VERSION "ADD"

NS_ :

BS_:

BU_: ADD

BO_ 688 ADD_ChassisFusion_0x2B0: 16 ADD
 SG_ ADDCooltFlowReqFrmADD : 79|6@0+ (0.25,0) [0|15.75] "Lpmin" Vector__XXX
 SG_ ADDFaultInfoFlag : 7|1@0+ (1,0) [0|1] "" Vector__XXX
 SG_ ADDTValFrmADD : 71|8@0+ (1,-40) [-40|215] "degC" Vector__XXX
 SG_ ADSLrnUnavlRsnFrmADD : 6|3@0+ (1,0) [0|4] "" Vector__XXX
 SG_ ADSParkSpdSwtStsFrmADD : 95|3@0+ (1,0) [0|7] "" Vector__XXX
 SG_ ADSParkSpdSwtUnavlRsnFrmADD : 3|4@0+ (1,0) [0|15] "" Vector__XXX
 SG_ APASwtStsFrmADD : 23|3@0+ (1,0) [0|7] "" Vector__XXX
 SG_ APASwtUnavlRsnFrmADD : 47|4@0+ (1,0) [0|15] "" Vector__XXX
 SG_ AutoVehCustEIPSwtFrmADD : 87|3@0+ (1,0) [0|4] "" Vector__XXX
 SG_ AutoVehCustEIPSwtRsnFrmADD : 84|2@0+ (1,0) [0|3] "" Vector__XXX
 SG_ AutoVehSrvAuthntStsFrmADD : 82|3@0+ (1,0) [0|4] "" Vector__XXX
 SG_ AutoVehSrvAuthntStsRsnFrmADD : 73|2@0+ (1,0) [0|3] "" Vector__XXX
 SG_ AvmCamTriggerModReqFrmADD : 91|2@0+ (1,0) [0|3] "" Vector__XXX
 SG_ AVPSwtStsFrmADD : 31|3@0+ (1,0) [0|7] "" Vector__XXX
 SG_ AVPSwtUnavlRsnFrmADD : 43|4@0+ (1,0) [0|15] "" Vector__XXX
 SG_ HPPBckGrLearFrmADD : 28|3@0+ (1,0) [0|7] "" Vector__XXX
 SG_ HPPBckGrLearUnavlRsnFrmADD : 55|4@0+ (1,0) [0|15] "" Vector__XXX
 SG_ HPPSwtStsFrmADD : 39|3@0+ (1,0) [0|7] "" Vector__XXX
 SG_ HPPSwtUnavlRsnFrmADD : 51|4@0+ (1,0) [0|15] "" Vector__XXX
 SG_ ParkSwtStsSigGrpChks : 15|8@0+ (1,0) [0|255] "" Vector__XXX
 SG_ ParkSwtStsSigGrpCntr : 19|4@0+ (1,0) [0|15] "" Vector__XXX
 SG_ RPASentryQuit : 92|1@0+ (1,0) [0|1] "" Vector__XXX

BO_ 693 ADD_ChassisFusion_0x2B5: 64 ADD
 SG_ ParkOutTarDirFrmADD : 143|2@0+ (1,0) [0|3] "" Vector__XXX
 SG_ ParkSlotTarFrmADD : 151|5@0+ (1,0) [0|31] "" Vector__XXX
 SG_ ParkTarPosnSigGrpChks : 135|8@0+ (1,0) [0|255] "" Vector__XXX
 SG_ ParkTarPosnSigGrpCntr : 139|4@0+ (1,0) [0|15] "" Vector__XXX
 SG_ PASBuzzerWarnMuteReqFrmADD : 119|1@0+ (1,0) [0|1] "" Vector__XXX
 SG_ PASDistanceLevSigGrpChks : 423|8@0+ (1,0) [0|255] "" Vector__XXX
 SG_ PASDistanceLevSigGrpCntr : 427|4@0+ (1,0) [0|15] "" Vector__XXX
 SG_ PASDistanceSystemGrpChks : 159|8@0+ (1,0) [0|255] "" Vector__XXX
 SG_ PASDistanceSystemGrpCntr : 163|4@0+ (1,0) [0|15] "" Vector__XXX
 SG_ PASFCBuzzerWarnFrmADD : 118|3@0+ (1,0) [0|7] "" Vector__XXX
 SG_ PASFLBuzzerSigGrpChks : 95|8@0+ (1,0) [0|255] "" Vector__XXX
 SG_ PASFLBuzzerSigGrpCntr : 99|4@0+ (1,0) [0|15] "" Vector__XXX
 SG_ PASFLBuzzerWarnFrmADD : 115|3@0+ (1,0) [0|7] "" Vector__XXX
 SG_ PASFLDistanceFrmADD : 175|10@0+ (1,0) [0|550] "cm" Vector__XXX
 SG_ PASFLDistanceLevFrmADD : 439|3@0+ (1,0) [0|7] "" Vector__XXX
 SG_ PASFMLDistanceFrmADD : 177|10@0+ (1,0) [0|550] "cm" Vector__XXX
 SG_ PASFMLDistanceLevFrmADD : 436|3@0+ (1,0) [0|7] "" Vector__XXX
 SG_ PASFMRDistanceFrmADD : 199|10@0+ (1,0) [0|550] "cm" Vector__XXX
 SG_ PASFMRDistanceLevFrmADD : 447|3@0+ (1,0) [0|7] "" Vector__XXX
 SG_ PASFRBuzzerWarnFrmADD : 111|3@0+ (1,0) [0|7] "" Vector__XXX
 SG_ PASFRDistanceFrmADD : 201|10@0+ (1,0) [0|550] "cm" Vector__XXX
 SG_ PASFRDistanceLevFrmADD : 444|3@0+ (1,0) [0|7] "" Vector__XXX
 SG_ PASFSLDistanceFrmADD : 367|10@0+ (1,0) [0|550] "cm" Vector__XXX
 SG_ PASFSLDistanceLevFrmADD : 455|3@0+ (1,0) [0|7] "" Vector__XXX
 SG_ PASFSRDistanceFrmADD : 369|10@0+ (1,0) [0|550] "cm" Vector__XXX
 SG_ PASFSRDistanceLevFrmADD : 452|3@0+ (1,0) [0|7] "" Vector__XXX
 SG_ PASRLBuzzerWarnFrmADD : 108|3@0+ (1,0) [0|7] "" Vector__XXX
 SG_ PASRLDistanceFrmADD : 223|10@0+ (1,0) [0|550] "cm" Vector__XXX
 SG_ PASRLDistanceLevFrmADD : 463|3@0+ (1,0) [0|7] "" Vector__XXX
 SG_ PASRMLDistanceFrmADD : 225|10@0+ (1,0) [0|550] "cm" Vector__XXX
 SG_ PASRMLDistanceLevFrmADD : 460|3@0+ (1,0) [0|7] "" Vector__XXX
 SG_ PASRMRDistanceFrmADD : 247|10@0+ (1,0) [0|550] "cm" Vector__XXX
 SG_ PASRMRDistanceLevFrmADD : 471|3@0+ (1,0) [0|7] "" Vector__XXX
 SG_ PASRRBuzzerWarnFrmADD : 127|3@0+ (1,0) [0|7] "" Vector__XXX
 SG_ PASRRDistanceFrmADD : 249|10@0+ (1,0) [0|550] "cm" Vector__XXX
 SG_ PASRRDistanceLevFrmADD : 468|3@0+ (1,0) [0|7] "" Vector__XXX
 SG_ PASRSLDistanceFrmADD : 391|10@0+ (1,0) [0|550] "cm" Vector__XXX
 SG_ PASRSLDistanceLevFrmADD : 479|3@0+ (1,0) [0|7] "" Vector__XXX
 SG_ PASRSRDistanceFrmADD : 393|10@0+ (1,0) [0|550] "cm" Vector__XXX
 SG_ PASRSRDistanceLevFrmADD : 476|3@0+ (1,0) [0|7] "" Vector__XXX
 SG_ PASSDWFLSideDistanceFrmADD : 271|10@0+ (1,0) [0|550] "cm" Vector__XXX
 SG_ PASSDWFLSideDistanceLevFrmADD : 487|3@0+ (1,0) [0|7] "" Vector__XXX
 SG_ PASSDWFMLSideDistanceFrmADD : 273|10@0+ (1,0) [0|550] "cm" Vector__XXX
 SG_ PASSDWFMLSideDistanceLevFrmADD : 484|3@0+ (1,0) [0|7] "" Vector__XXX
 SG_ PASSDWFMRSideDistanceFrmADD : 295|10@0+ (1,0) [0|550] "cm" Vector__XXX
 SG_ PASSDWFMRSideDistanceLevFrmADD : 495|3@0+ (1,0) [0|7] "" Vector__XXX
 SG_ PASSDWFRSideDistanceFrmADD : 297|10@0+ (1,0) [0|550] "cm" Vector__XXX
 SG_ PASSDWFRSideDistanceLevFrmADD : 492|3@0+ (1,0) [0|7] "" Vector__XXX
 SG_ PASSDWRLSideDistanceFrmADD : 319|10@0+ (1,0) [0|550] "cm" Vector__XXX
 SG_ PASSDWRLSideDistanceLevFrmADD : 503|3@0+ (1,0) [0|7] "" Vector__XXX
 SG_ PASSDWRMLSideDistanceFrmADD : 321|10@0+ (1,0) [0|550] "cm" Vector__XXX
 SG_ PASSDWRMLSideDistanceLevFrmADD : 500|3@0+ (1,0) [0|7] "" Vector__XXX
 SG_ PASSDWRMRSideDistanceFrmADD : 343|10@0+ (1,0) [0|550] "cm" Vector__XXX
 SG_ PASSDWRMRSideDistanceLevFrmADD : 511|3@0+ (1,0) [0|7] "" Vector__XXX
 SG_ PASSDWRRSideDistanceFrmADD : 345|10@0+ (1,0) [0|550] "cm" Vector__XXX
 SG_ PASSDWRRSideDistanceLevFrmADD : 508|3@0+ (1,0) [0|7] "" Vector__XXX

BO_ 775 ADD_ChassisFusion_0x307: 32 ADD
 SG_ ParkProgressSigLFPosXFrmADD : 55|16@0+ (0.01,-327.67) [-327.67|327.68] "m" Vector__XXX
 SG_ ParkProgressSigLFPosYFrmADD : 71|16@0+ (0.01,-327.67) [-327.67|327.68] "m" Vector__XXX
 SG_ ParkProgressSigLRPosXFrmADD : 87|16@0+ (0.01,-327.67) [-327.67|327.68] "m" Vector__XXX
 SG_ ParkProgressSigLRPosYFrmADD : 103|16@0+ (0.01,-327.67) [-327.67|327.68] "m" Vector__XXX
 SG_ ParkProgressSigRFPosXFrmADD : 119|16@0+ (0.01,-327.67) [-327.67|327.68] "m" Vector__XXX
 SG_ ParkProgressSigRFPosYFrmADD : 135|16@0+ (0.01,-327.67) [-327.67|327.68] "m" Vector__XXX
 SG_ ParkProgressSigRRPosXFrmADD : 151|16@0+ (0.01,-327.67) [-327.67|327.68] "m" Vector__XXX
 SG_ ParkProgressSigRRPosYFrmADD : 167|16@0+ (0.01,-327.67) [-327.67|327.68] "m" Vector__XXX
 SG_ PASProgressSigGrpChks : 39|8@0+ (1,0) [0|255] "" Vector__XXX
 SG_ PASProgressSigGrpCntr : 43|4@0+ (1,0) [0|15] "" Vector__XXX
 SG_ PASSubFunAvaiFrmADD : 15|3@0+ (1,0) [0|7] "" Vector__XXX
 SG_ PASWorkingModeFrmADD : 23|3@0+ (1,0) [0|7] "" Vector__XXX
 SG_ PASWorkingModeSigGrpChks : 7|8@0+ (1,0) [0|255] "" Vector__XXX
 SG_ PASWorkingModeSigGrpCntr : 11|4@0+ (1,0) [0|15] "" Vector__XXX

BO_ 873 ADD_ChassisFusion_0x369: 8 ADD
 SG_ LowPwrReqFrLdrFrmADD : 23|2@0+ (1,0) [0|2] "" Vector__XXX
 SG_ LowPwrReqFrRdrFrmADD : 21|2@0+ (1,0) [0|2] "" Vector__XXX

BO_ 238 ADD_ChassisFusion_0xEE: 32 ADD
 SG_ ADD2BLEMForRPA00 : 7|64@0+ (1,0) [0|1.84467440737096E+019] "" Vector__XXX
 SG_ ADD2BLEMForRPA00FV : 215|16@0+ (1,0) [0|65535] "" Vector__XXX
 SG_ ADD2BLEMForRPA00MAC : 231|32@0+ (1,0) [0|0] "" Vector__XXX
 SG_ ADD2BLEMForRPA01 : 71|64@0+ (1,0) [0|1.84467440737096E+019] "" Vector__XXX
 SG_ ADD2BLEMForRPA02 : 135|64@0+ (1,0) [0|1.84467440737096E+019] "" Vector__XXX
 SG_ ADD2BLEMForRPA03 : 199|16@0+ (1,0) [0|65535] "" Vector__XXX

BO_ 239 ADD_ChassisFusion_0xEF: 24 ADD
 SG_ ADDIMUSigGrpChks : 7|8@0+ (1,0) [0|255] "" Vector__XXX
 SG_ ADDIMUSigGrpCntr : 11|4@0+ (1,0) [0|15] "" Vector__XXX
 SG_ XAccelStaFrmADD : 33|2@0+ (1,0) [0|3] "" Vector__XXX
 SG_ XAccelValFrmADD : 23|20@0+ (0.001,-98.1) [-98.1|98.1] "m/s^2" Vector__XXX
 SG_ XAngRateStaFrmADD : 177|2@0+ (1,0) [0|3] "" Vector__XXX
 SG_ XAngRateValFrmADD : 47|22@0+ (1E-005,-8.72665) [-8.72665|8.72665] "rad/s" Vector__XXX
 SG_ YAccelStaFrmADD : 161|2@0+ (1,0) [0|3] "" Vector__XXX
 SG_ YAccelValFrmADD : 71|20@0+ (0.001,-98.1) [-98.1|98.1] "m/s^2" Vector__XXX
 SG_ YAngRateStaFrmADD : 163|2@0+ (1,0) [0|3] "" Vector__XXX
 SG_ YAngRateValFrmADD : 95|22@0+ (1E-005,-8.72665) [-8.72665|8.72665] "rad/s" Vector__XXX
 SG_ ZAccelStaFrmADD : 171|2@0+ (1,0) [0|3] "" Vector__XXX
 SG_ ZAccelValFrmADD : 119|20@0+ (0.001,-98.1) [-98.1|98.1] "m/s^2" Vector__XXX
 SG_ ZAngRateStaFrmADD : 169|2@0+ (1,0) [0|3] "" Vector__XXX
 SG_ ZAngRateValFrmADD : 143|22@0+ (1E-005,-8.72665) [-8.72665|8.72665] "rad/s" Vector__XXX

BO_ 1331 ADDChassisFusionCanfdNMFrA: 8 ADD
 SG_ ADDChassisBkpActiveWakeup : 12|1@0+ (1,0) [0|1] "" Vector__XXX
 SG_ ADDChassisBkpNodeAddress : 7|8@0+ (1,0) [0|255] "" Vector__XXX
 SG_ ADDChassisBkpRepeatMsgReq : 8|1@0+ (1,0) [0|1] "" Vector__XXX
 SG_ ADDChassisBkpRepeatMsgSt : 16|1@0+ (1,0) [0|1] "" Vector__XXX
 SG_ NMKeepAwkRsnADD : 48|9@0+ (1,0) [0|511] "" Vector__XXX
 SG_ UDB17ADD : 17|1@0+ (1,0) [0|1] "" Vector__XXX
 SG_ UDB18ADD : 18|1@0+ (1,0) [0|1] "" Vector__XXX
 SG_ UDB19ADD : 19|1@0+ (1,0) [0|1] "" Vector__XXX
 SG_ UDB20ADD : 20|1@0+ (1,0) [0|1] "" Vector__XXX
 SG_ UDB21ADD : 21|1@0+ (1,0) [0|1] "" Vector__XXX
 SG_ UDB22ADD : 22|1@0+ (1,0) [0|1] "" Vector__XXX
 SG_ UDB23ADD : 23|1@0+ (1,0) [0|1] "" Vector__XXX
 SG_ UDB24ADD : 24|1@0+ (1,0) [0|1] "" Vector__XXX
 SG_ UDB25ADD : 25|1@0+ (1,0) [0|1] "" Vector__XXX
 SG_ UDB26ADD : 26|1@0+ (1,0) [0|1] "" Vector__XXX
 SG_ UDB27ADD : 27|1@0+ (1,0) [0|1] "" Vector__XXX
 SG_ UDB28ADD : 28|1@0+ (1,0) [0|1] "" Vector__XXX
 SG_ UDB29ADD : 29|1@0+ (1,0) [0|1] "" Vector__XXX
 SG_ UDB30ADD : 30|1@0+ (1,0) [0|1] "" Vector__XXX
 SG_ UDB31ADD : 31|1@0+ (1,0) [0|1] "" Vector__XXX
 SG_ UDB32ADD : 32|1@0+ (1,0) [0|1] "" Vector__XXX
 SG_ UDB33ADD : 33|1@0+ (1,0) [0|1] "" Vector__XXX
 SG_ UDB34ADD : 34|1@0+ (1,0) [0|1] "" Vector__XXX
 SG_ UDB35ADD : 35|1@0+ (1,0) [0|1] "" Vector__XXX
 SG_ UDB36ADD : 36|1@0+ (1,0) [0|1] "" Vector__XXX
 SG_ UDB37ADD : 37|1@0+ (1,0) [0|1] "" Vector__XXX
 SG_ UDB38ADD : 38|1@0+ (1,0) [0|1] "" Vector__XXX
 SG_ UDB39ADD : 39|1@0+ (1,0) [0|1] "" Vector__XXX
 SG_ UDB40ADD : 40|1@0+ (1,0) [0|1] "" Vector__XXX
 SG_ UDB41ADD : 41|1@0+ (1,0) [0|1] "" Vector__XXX
 SG_ UDB42ADD : 42|1@0+ (1,0) [0|1] "" Vector__XXX
 SG_ UDB43ADD : 43|1@0+ (1,0) [0|1] "" Vector__XXX
 SG_ UDB44ADD : 44|1@0+ (1,0) [0|1] "" Vector__XXX
 SG_ UDB45ADD : 45|1@0+ (1,0) [0|1] "" Vector__XXX
 SG_ UDB46ADD : 46|1@0+ (1,0) [0|1] "" Vector__XXX
 SG_ UDB47ADD : 47|1@0+ (1,0) [0|1] "" Vector__XXX

BO_ 1326 ADDChassisFusionCanfdNMFrB: 8 ADD
 SG_ ADDChassisBkpActiveWakeup1 : 12|1@0+ (1,0) [0|1] "" Vector__XXX
 SG_ ADDChassisBkpNodeAddress1 : 7|8@0+ (1,0) [0|255] "" Vector__XXX
 SG_ ADDChassisBkpRepeatMsgReq1 : 8|1@0+ (1,0) [0|1] "" Vector__XXX
 SG_ ADDChassisBkpRepeatMsgSt1 : 16|1@0+ (1,0) [0|1] "" Vector__XXX
 SG_ NMKeepAwkRsnADD : 48|9@0+ (1,0) [0|511] "" Vector__XXX
 SG_ UDB17ADD : 17|1@0+ (1,0) [0|1] "" Vector__XXX
 SG_ UDB18ADD : 18|1@0+ (1,0) [0|1] "" Vector__XXX
 SG_ UDB19ADD : 19|1@0+ (1,0) [0|1] "" Vector__XXX
 SG_ UDB20ADD : 20|1@0+ (1,0) [0|1] "" Vector__XXX
 SG_ UDB21ADD : 21|1@0+ (1,0) [0|1] "" Vector__XXX
 SG_ UDB22ADD : 22|1@0+ (1,0) [0|1] "" Vector__XXX
 SG_ UDB23ADD : 23|1@0+ (1,0) [0|1] "" Vector__XXX
 SG_ UDB24ADD : 24|1@0+ (1,0) [0|1] "" Vector__XXX
 SG_ UDB25ADD : 25|1@0+ (1,0) [0|1] "" Vector__XXX
 SG_ UDB26ADD : 26|1@0+ (1,0) [0|1] "" Vector__XXX
 SG_ UDB27ADD : 27|1@0+ (1,0) [0|1] "" Vector__XXX
 SG_ UDB28ADD : 28|1@0+ (1,0) [0|1] "" Vector__XXX
 SG_ UDB29ADD : 29|1@0+ (1,0) [0|1] "" Vector__XXX
 SG_ UDB30ADD : 30|1@0+ (1,0) [0|1] "" Vector__XXX
 SG_ UDB31ADD : 31|1@0+ (1,0) [0|1] "" Vector__XXX
 SG_ UDB32ADD : 32|1@0+ (1,0) [0|1] "" Vector__XXX
 SG_ UDB33ADD : 33|1@0+ (1,0) [0|1] "" Vector__XXX
 SG_ UDB34ADD : 34|1@0+ (1,0) [0|1] "" Vector__XXX
 SG_ UDB35ADD : 35|1@0+ (1,0) [0|1] "" Vector__XXX
 SG_ UDB36ADD : 36|1@0+ (1,0) [0|1] "" Vector__XXX
 SG_ UDB37ADD : 37|1@0+ (1,0) [0|1] "" Vector__XXX
 SG_ UDB38ADD : 38|1@0+ (1,0) [0|1] "" Vector__XXX
 SG_ UDB39ADD : 39|1@0+ (1,0) [0|1] "" Vector__XXX
 SG_ UDB40ADD : 40|1@0+ (1,0) [0|1] "" Vector__XXX
 SG_ UDB41ADD : 41|1@0+ (1,0) [0|1] "" Vector__XXX
 SG_ UDB42ADD : 42|1@0+ (1,0) [0|1] "" Vector__XXX
 SG_ UDB43ADD : 43|1@0+ (1,0) [0|1] "" Vector__XXX
 SG_ UDB44ADD : 44|1@0+ (1,0) [0|1] "" Vector__XXX
 SG_ UDB45ADD : 45|1@0+ (1,0) [0|1] "" Vector__XXX
 SG_ UDB46ADD : 46|1@0+ (1,0) [0|1] "" Vector__XXX
 SG_ UDB47ADD : 47|1@0+ (1,0) [0|1] "" Vector__XXX

BO_ 487 BCP_ChassisFusion_0x1E7: 24 Vector__XXX
 SG_ BcpBrkSysIndcnBkpSigGrpChks : 103|8@0+ (1,0) [0|255] ""  ADD
 SG_ BcpBrkSysIndcnBkpSigGrpCntr : 107|4@0+ (1,0) [0|15] ""  ADD
 SG_ BrkSysBrkPedlAppld : 111|1@0+ (1,0) [0|1] ""  ADD
 SG_ BrkSysBrkPedlAppldVld : 110|2@0+ (1,0) [0|3] ""  ADD
 SG_ BrkSysEnaActvCtrlByDrvr : 108|1@0+ (1,0) [0|1] ""  ADD
 SG_ BrkSysFTarDrvr : 127|11@0+ (64,-131008) [-131008|0] "N"  ADD
 SG_ BrkSysFTarDrvrVld : 132|2@0+ (1,0) [0|3] ""  ADD
 SG_ BrkSysPRednPotnl : 119|8@0+ (0.5,0) [0|120] "bar"  ADD
 SG_ BrkSysPRednPotnlVld : 130|2@0+ (1,0) [0|3] ""  ADD
 SG_ BrkSysWarnLampReq : 143|2@0+ (1,0) [0|3] ""  ADD

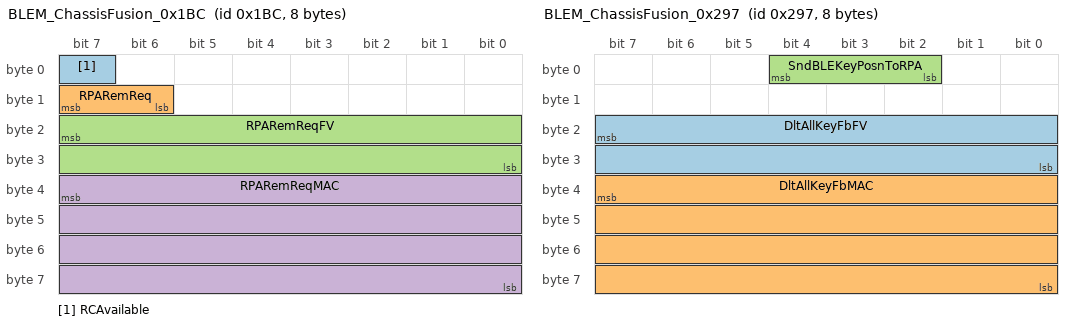
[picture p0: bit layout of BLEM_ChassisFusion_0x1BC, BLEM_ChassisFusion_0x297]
BO_ 444 BLEM_ChassisFusion_0x1BC: 8 Vector__XXX
 SG_ RCAvailable : 7|1@0+ (1,0) [0|1] ""  ADD
 SG_ RPARemReq : 15|2@0+ (1,0) [0|3] ""  ADD
 SG_ RPARemReqFV : 23|16@0+ (1,0) [0|65535] ""  ADD
 SG_ RPARemReqMAC : 39|32@0+ (1,0) [0|0] ""  ADD

BO_ 657 BLEM_ChassisFusion_0x291: 64 Vector__XXX
 SG_ BLEM2VCCDForLocn10 : 7|32@0+ (1,0) [0|4294967295] ""  ADD
 SG_ BLEM2VCCDForLocn11 : 39|32@0+ (1,0) [0|4294967295] ""  ADD
 SG_ BLEM2VCCDForLocn12 : 71|32@0+ (1,0) [0|4294967295] ""  ADD
 SG_ BLEM2VCCDForLocn13 : 103|32@0+ (1,0) [0|4294967295] ""  ADD
 SG_ BLEM2VCCDForLocn14 : 135|32@0+ (1,0) [0|4294967295] ""  ADD
 SG_ BLEM2VCCDForLocn15 : 167|32@0+ (1,0) [0|4294967295] ""  ADD
 SG_ BLEM2VCCDForLocn16 : 199|32@0+ (1,0) [0|4294967295] ""  ADD
 SG_ BLEM2VCCDForLocn17 : 231|32@0+ (1,0) [0|4294967295] ""  ADD
 SG_ BLEM2VCCDForLocn18 : 263|32@0+ (1,0) [0|4294967295] ""  ADD
 SG_ BLEM2VCCDForLocn19 : 295|32@0+ (1,0) [0|4294967295] ""  ADD
 SG_ BLEM2VCCDForLocn1A : 327|32@0+ (1,0) [0|4294967295] ""  ADD
 SG_ BLEM2VCCDForLocn1B : 359|32@0+ (1,0) [0|4294967295] ""  ADD
 SG_ BLEM2VCCDForLocn1C : 391|32@0+ (1,0) [0|4294967295] ""  ADD
 SG_ BLEM2VCCDForLocn1D : 423|32@0+ (1,0) [0|4294967295] ""  ADD
 SG_ BLEM2VCCDForLocn1F : 455|16@0+ (1,0) [0|65535] ""  ADD
 SG_ BLEM2VCCDForLocn1FV : 471|16@0+ (1,0) [0|65535] ""  ADD
 SG_ BLEM2VCCDForLocn1MAC : 487|32@0+ (1,0) [0|0] ""  ADD

BO_ 663 BLEM_ChassisFusion_0x297: 8 Vector__XXX
 SG_ DltAllKeyFbFV : 23|16@0+ (1,0) [0|65535] ""  ADD
 SG_ DltAllKeyFbMAC : 39|32@0+ (1,0) [0|0] ""  ADD
 SG_ SndBLEKeyPosnToRPA : 4|3@0+ (1,0) [0|7] ""  ADD

BO_ 665 BLEM_ChassisFusion_0x299: 64 Vector__XXX
 SG_ BLEM2VCCDForLocn20 : 7|32@0+ (1,0) [0|4294967295] ""  ADD
 SG_ BLEM2VCCDForLocn21 : 39|32@0+ (1,0) [0|4294967295] ""  ADD
 SG_ BLEM2VCCDForLocn22 : 71|32@0+ (1,0) [0|4294967295] ""  ADD
 SG_ BLEM2VCCDForLocn23 : 103|32@0+ (1,0) [0|4294967295] ""  ADD
 SG_ BLEM2VCCDForLocn24 : 135|32@0+ (1,0) [0|4294967295] ""  ADD
 SG_ BLEM2VCCDForLocn25 : 167|32@0+ (1,0) [0|4294967295] ""  ADD
 SG_ BLEM2VCCDForLocn26 : 199|32@0+ (1,0) [0|4294967295] ""  ADD
 SG_ BLEM2VCCDForLocn27 : 231|32@0+ (1,0) [0|4294967295] ""  ADD
 SG_ BLEM2VCCDForLocn28 : 263|32@0+ (1,0) [0|4294967295] ""  ADD
 SG_ BLEM2VCCDForLocn29 : 295|32@0+ (1,0) [0|4294967295] ""  ADD
 SG_ BLEM2VCCDForLocn2A : 327|32@0+ (1,0) [0|4294967295] ""  ADD
 SG_ BLEM2VCCDForLocn2B : 359|32@0+ (1,0) [0|4294967295] ""  ADD
 SG_ BLEM2VCCDForLocn2C : 391|32@0+ (1,0) [0|4294967295] ""  ADD
 SG_ BLEM2VCCDForLocn2D : 423|32@0+ (1,0) [0|4294967295] ""  ADD
 SG_ BLEM2VCCDForLocn2F : 455|16@0+ (1,0) [0|65535] ""  ADD
 SG_ BLEM2VCCDForLocn2FV : 471|16@0+ (1,0) [0|65535] ""  ADD
 SG_ BLEM2VCCDForLocn2MAC : 487|32@0+ (1,0) [0|0] ""  ADD

BO_ 758 BLEM_ChassisFusion_0x2F6: 16 Vector__XXX
 SG_ FrntLeTyrePVal : 31|8@0+ (2.75,0) [0|698.5] "kpa"  ADD
 SG_ FrntLeTyrePWarn : 19|2@0+ (1,0) [0|3] ""  ADD
 SG_ FrntRiTyrePVal : 39|8@0+ (2.75,0) [0|698.5] "kpa"  ADD
 SG_ FrntRiTyrePWarn : 17|2@0+ (1,0) [0|3] ""  ADD
 SG_ ReLeTyrePVal : 7|8@0+ (2.75,0) [0|698.5] "kpa"  ADD
 SG_ ReLeTyrePWarn : 23|2@0+ (1,0) [0|3] ""  ADD
 SG_ ReRiTyrePVal : 15|8@0+ (2.75,0) [0|698.5] "kpa"  ADD
 SG_ ReRiTyrePWarn : 21|2@0+ (1,0) [0|3] ""  ADD
 SG_ TyrePWarnFV : 87|16@0+ (1,0) [0|65535] ""  ADD
 SG_ TyrePWarnMAC : 103|32@0+ (1,0) [0|4294967295] ""  ADD

BO_ 817 BLEM_ChassisFusion_0x331: 64 Vector__XXX
 SG_ BLEM2VCCDForLocn40 : 135|32@0+ (1,0) [0|4294967295] ""  ADD
 SG_ BLEM2VCCDForLocn41 : 167|32@0+ (1,0) [0|4294967295] ""  ADD
 SG_ BLEM2VCCDForLocn42 : 199|32@0+ (1,0) [0|4294967295] ""  ADD
 SG_ BLEM2VCCDForLocn43 : 231|32@0+ (1,0) [0|4294967295] ""  ADD
 SG_ BLEM2VCCDForLocn44 : 7|32@0+ (1,0) [0|4294967295] ""  ADD
 SG_ BLEM2VCCDForLocn45 : 39|32@0+ (1,0) [0|4294967295] ""  ADD
 SG_ BLEM2VCCDForLocn46 : 71|32@0+ (1,0) [0|4294967295] ""  ADD
 SG_ BLEM2VCCDForLocn47 : 103|32@0+ (1,0) [0|4294967295] ""  ADD
 SG_ BLEM2VCCDForLocn48 : 263|32@0+ (1,0) [0|4294967295] ""  ADD
 SG_ BLEM2VCCDForLocn49 : 295|32@0+ (1,0) [0|4294967295] ""  ADD
 SG_ BLEM2VCCDForLocn4A : 327|32@0+ (1,0) [0|4294967295] ""  ADD
 SG_ BLEM2VCCDForLocn4B : 359|32@0+ (1,0) [0|4294967295] ""  ADD
 SG_ BLEM2VCCDForLocn4C : 391|32@0+ (1,0) [0|4294967295] ""  ADD
 SG_ BLEM2VCCDForLocn4D : 423|32@0+ (1,0) [0|4294967295] ""  ADD
 SG_ BLEM2VCCDForLocn4F : 455|16@0+ (1,0) [0|65535] ""  ADD
 SG_ BLEM2VCCDForLocn4FV : 471|16@0+ (1,0) [0|65535] ""  ADD
 SG_ BLEM2VCCDForLocn4MAC : 487|32@0+ (1,0) [0|0] ""  ADD

BO_ 825 BLEM_ChassisFusion_0x339: 32 Vector__XXX
 SG_ BLEM2ADDForRPA00 : 7|64@0+ (1,0) [0|1.84467440737096E+019] ""  ADD
 SG_ BLEM2ADDForRPA00FV : 215|16@0+ (1,0) [0|65535] ""  ADD
 SG_ BLEM2ADDForRPA00MAC : 231|32@0+ (1,0) [0|0] ""  ADD
 SG_ BLEM2ADDForRPA01 : 71|64@0+ (1,0) [0|1.84467440737096E+019] ""  ADD
 SG_ BLEM2ADDForRPA02 : 135|64@0+ (1,0) [0|1.84467440737096E+019] ""  ADD
 SG_ BLEM2ADDForRPA03 : 199|16@0+ (1,0) [0|65535] ""  ADD

BO_ 826 BLEM_ChassisFusion_0x33A: 64 Vector__XXX
 SG_ BLEM2VCCDForLocn30 : 7|32@0+ (1,0) [0|4294967295] ""  ADD
 SG_ BLEM2VCCDForLocn31 : 39|32@0+ (1,0) [0|4294967295] ""  ADD
 SG_ BLEM2VCCDForLocn32 : 71|32@0+ (1,0) [0|4294967295] ""  ADD
 SG_ BLEM2VCCDForLocn33 : 103|32@0+ (1,0) [0|4294967295] ""  ADD
 SG_ BLEM2VCCDForLocn34 : 135|32@0+ (1,0) [0|4294967295] ""  ADD
 SG_ BLEM2VCCDForLocn35 : 167|32@0+ (1,0) [0|4294967295] ""  ADD
 SG_ BLEM2VCCDForLocn36 : 199|32@0+ (1,0) [0|4294967295] ""  ADD
 SG_ BLEM2VCCDForLocn37 : 231|32@0+ (1,0) [0|4294967295] ""  ADD
 SG_ BLEM2VCCDForLocn38 : 263|32@0+ (1,0) [0|4294967295] ""  ADD
 SG_ BLEM2VCCDForLocn39 : 295|32@0+ (1,0) [0|4294967295] ""  ADD
 SG_ BLEM2VCCDForLocn3A : 327|32@0+ (1,0) [0|4294967295] ""  ADD
 SG_ BLEM2VCCDForLocn3B : 359|32@0+ (1,0) [0|4294967295] ""  ADD
 SG_ BLEM2VCCDForLocn3C : 391|32@0+ (1,0) [0|4294967295] ""  ADD
 SG_ BLEM2VCCDForLocn3D : 423|32@0+ (1,0) [0|4294967295] ""  ADD
 SG_ BLEM2VCCDForLocn3F : 455|16@0+ (1,0) [0|65535] ""  ADD
 SG_ BLEM2VCCDForLocn3FV : 471|16@0+ (1,0) [0|65535] ""  ADD
 SG_ BLEM2VCCDForLocn3MAC : 487|32@0+ (1,0) [0|0] ""  ADD

BO_ 827 BLEM_ChassisFusion_0x33B: 64 Vector__XXX
 SG_ BLEM2VCCDForRkeReq00 : 7|32@0+ (1,0) [0|4294967295] ""  ADD
 SG_ BLEM2VCCDForRkeReq01 : 39|32@0+ (1,0) [0|4294967295] ""  ADD
 SG_ BLEM2VCCDForRkeReq02 : 71|32@0+ (1,0) [0|4294967295] ""  ADD
 SG_ BLEM2VCCDForRkeReq03 : 103|32@0+ (1,0) [0|4294967295] ""  ADD
 SG_ BLEM2VCCDForRkeReq04 : 135|32@0+ (1,0) [0|4294967295] ""  ADD
 SG_ BLEM2VCCDForRkeReq05 : 167|32@0+ (1,0) [0|4294967295] ""  ADD
 SG_ BLEM2VCCDForRkeReq06 : 199|32@0+ (1,0) [0|4294967295] ""  ADD
 SG_ BLEM2VCCDForRkeReq07 : 231|32@0+ (1,0) [0|4294967295] ""  ADD
 SG_ BLEM2VCCDForRkeReq08 : 263|32@0+ (1,0) [0|4294967295] ""  ADD
 SG_ BLEM2VCCDForRkeReq09 : 295|32@0+ (1,0) [0|4294967295] ""  ADD
 SG_ BLEM2VCCDForRkeReq10 : 327|32@0+ (1,0) [0|4294967295] ""  ADD
 SG_ BLEM2VCCDForRkeReq11 : 359|32@0+ (1,0) [0|4294967295] ""  ADD
 SG_ BLEM2VCCDForRkeReq12 : 391|32@0+ (1,0) [0|4294967295] ""  ADD
 SG_ BLEM2VCCDForRkeReq13 : 423|32@0+ (1,0) [0|4294967295] ""  ADD
 SG_ BLEM2VCCDForRkeReq14 : 455|16@0+ (1,0) [0|65535] ""  ADD
 SG_ BLEM2VCCDForRkeReqFV : 471|16@0+ (1,0) [0|65535] ""  ADD
 SG_ BLEM2VCCDForRkeReqMAC : 487|32@0+ (1,0) [0|0] ""  ADD

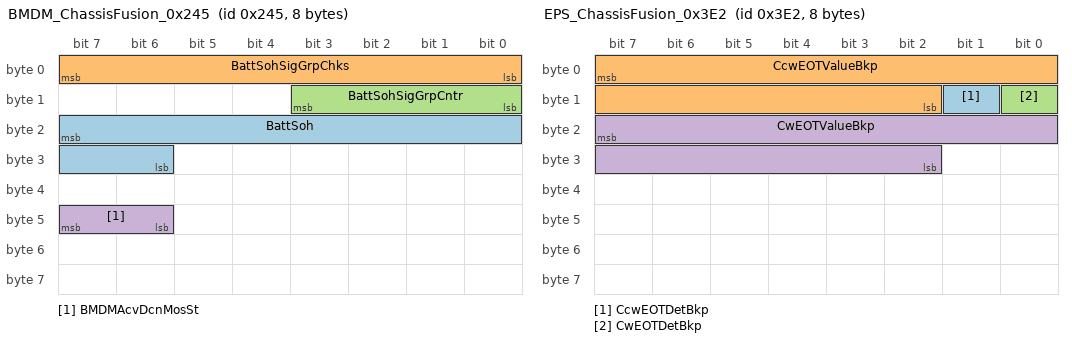
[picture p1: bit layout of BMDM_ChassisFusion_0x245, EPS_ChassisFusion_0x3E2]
BO_ 581 BMDM_ChassisFusion_0x245: 8 Vector__XXX
 SG_ BattSoh : 23|10@0+ (0.1,0) [0|102.3] "%"  ADD
 SG_ BattSohSigGrpChks : 7|8@0+ (1,0) [0|255] ""  ADD
 SG_ BattSohSigGrpCntr : 11|4@0+ (1,0) [0|15] ""  ADD
 SG_ BMDMAcvDcnMosSt : 47|2@0+ (1,0) [0|3] ""  ADD

BO_ 355 EPS_ChassisFusion_0x163: 16 Vector__XXX
 SG_ AVPHPPCtrlAvlStsBkp : 71|2@0+ (1,0) [0|3] ""  ADD
 SG_ AVPHPPCtrStsBkp : 56|1@0+ (1,0) [0|1] ""  ADD
 SG_ AVPHPPReqFbStsBkp : 59|3@0+ (1,0) [0|7] ""  ADD
 SG_ AVPHPPReqFltStsBkp : 63|4@0+ (1,0) [0|15] ""  ADD
 SG_ EPSAVPHPPCtrlStsBkpSigGrpChks : 47|8@0+ (1,0) [0|255] ""  ADD
 SG_ EPSAVPHPPCtrlStsBkpSigGrpCntr : 51|4@0+ (1,0) [0|15] ""  ADD
 SG_ FailrStsBkp : 38|3@0+ (1,0) [0|7] ""  ADD
 SG_ FailrStsBkpSigGrpChks : 31|8@0+ (1,0) [0|255] ""  ADD
 SG_ FailrStsBkpSigGrpCntr : 35|4@0+ (1,0) [0|15] ""  ADD

BO_ 994 EPS_ChassisFusion_0x3E2: 8 Vector__XXX
 SG_ CcwEOTDetBkp : 9|1@0+ (1,0) [0|1] ""  ADD
 SG_ CcwEOTValueBkp : 7|14@0+ (0.0625,0) [0|780] ""  ADD
 SG_ CwEOTDetBkp : 8|1@0+ (1,0) [0|1] ""  ADD
 SG_ CwEOTValueBkp : 23|14@0+ (0.0625,-780) [-780|0] "deg"  ADD

BO_ 200 EPS_ChassisFusion_0xC8: 16 Vector__XXX
 SG_ PinionAglSpdBkpV2C : 71|12@0- (1,0) [-2048|2047] "deg/s"  ADD
 SG_ PinionSteerAglBkp : 22|15@0- (0.0625,0) [-780|780] "°(deg)"  ADD
 SG_ PinionSteerAglBkpV2C : 87|15@0- (0.0625,0) [-780|780] "°（deg）"  ADD
 SG_ PinionSteerAglSpdBkp : 55|12@0- (1,0) [-2048|2047] "deg/s"  ADD
 SG_ PinionSteerAglSpdVldBkp : 59|1@0+ (1,0) [0|1] ""  ADD
 SG_ PinionSteerAglSpdVldBkpV2C : 75|1@0+ (1,0) [0|1] ""  ADD
 SG_ PinionSteerAglVldBkp : 23|1@0+ (1,0) [0|1] ""  ADD
 SG_ PinionSteerAglVldBkpV2C : 74|1@0+ (1,0) [0|1] ""  ADD
 SG_ SteeringWhlSignalBkpSigGrpChks : 7|8@0+ (1,0) [0|255] ""  ADD
 SG_ SteeringWhlSignalBkpSigGrpCntr : 11|4@0+ (1,0) [0|15] ""  ADD
 SG_ SteerWhlTqBkp : 39|11@0- (0.01,0) [-10.24|10.23] "Nm"  ADD
 SG_ SteerWhlTqVldBkp : 44|1@0+ (1,0) [0|1] ""  ADD

BO_ 515 FZCU_ChassisFusion_0x203: 16 Vector__XXX
 SG_ VCUExtmPfmncMod : 28|1@0+ (1,0) [0|1] ""  ADD
 SG_ VCUTrlrModStSts : 39|1@0+ (1,0) [0|1] ""  ADD
 SG_ VCUWashModStSts : 27|1@0+ (1,0) [0|1] ""  ADD
 SG_ VDMMueEstdForADD : 38|4@0+ (0.1,0) [0|1.5] ""  ADD

BO_ 656 FZCU_ChassisFusion_0x290: 32 Vector__XXX
 SG_ ADDCooltCircFlowEstimd : 119|10@0+ (0.05,0) [0|51.15] "L/min"  ADD
 SG_ AmbTEstimd : 103|16@0+ (0.01,-80) [-80|175] "degC"  ADD
 SG_ AmbTEstimdVld : 91|1@0+ (1,0) [0|1] ""  ADD
 SG_ EdsCircCooltT : 151|16@0+ (0.01,-80) [-80|175] "degC"  ADD
 SG_ EdsCircCooltTSnsrU : 167|16@0+ (0.1,0) [0|5000] "mV"  ADD
 SG_ EdsCircCooltTVld : 89|1@0+ (1,0) [0|1] ""  ADD
 SG_ InsEgyCnsSigGrpChks : 7|8@0+ (1,0) [0|255] ""  ADD
 SG_ InsEgyCnsSigGrpCntr : 11|4@0+ (1,0) [0|15] ""  ADD
 SG_ LRR2LoPwrSplySts : 125|1@0+ (1,0) [0|1] ""  ADD
 SG_ LRRLoPwrSplySts : 88|1@0+ (1,0) [0|1] ""  ADD
 SG_ VCUBattOverHeatWarn : 201|1@0+ (1,0) [0|1] ""  ADD
 SG_ VCUDrvMotFltWarn : 200|1@0+ (1,0) [0|1] ""  ADD
 SG_ VCUDrvMotOverHeatWarn : 215|1@0+ (1,0) [0|1] ""  ADD
 SG_ VCUDrvSysLimdWarn : 214|1@0+ (1,0) [0|1] ""  ADD
 SG_ VCUEgyCnsInCurDrvCyc : 23|18@0+ (0.01,-200) [-200|200] "kwh"  ADD
 SG_ VCUEstimdCrsRng : 71|11@0+ (1,0) [0|2046] ""  ADD
 SG_ VCUEstimdCrsRngForCltc : 74|11@0+ (1,0) [0|2047] ""  ADD
 SG_ VCUEstimdCrsRngVld : 76|1@0+ (1,0) [0|1] ""  ADD
 SG_ VCUGearChgFailInde : 207|4@0+ (1,0) [0|15] ""  ADD
 SG_ VCUHvBattSysFltIndcr : 213|1@0+ (1,0) [0|1] ""  ADD
 SG_ VCUHvBattSysFltWarn : 212|1@0+ (1,0) [0|1] ""  ADD
 SG_ VCUHvPwrSysCutOff : 211|1@0+ (1,0) [0|1] ""  ADD
 SG_ VCUHVSysFltWarnSts : 199|4@0+ (1,0) [0|15] ""  ADD
 SG_ VCUInsEgyCnsDurgDrvg : 55|11@0+ (0.1,-100) [-100|100] ""  ADD
 SG_ VCUInsEgyCnsDurgStsl : 32|9@0+ (0.1,0) [0|50] ""  ADD
 SG_ VCUInsEgyCnsFlg : 60|1@0+ (1,0) [0|1] ""  ADD
 SG_ VCULoSocWarngMsg : 203|2@0+ (1,0) [0|2] ""  ADD
 SG_ VCUPrpsnPwrDrt : 210|1@0+ (1,0) [0|1] ""  ADD
 SG_ VCUThermRunawayErrAlrm : 209|1@0+ (1,0) [0|1] ""  ADD
 SG_ VCUVehSysFltWarn : 208|1@0+ (1,0) [0|1] ""  ADD
 SG_ VehSysFltWarnSigGrpChks : 191|8@0+ (1,0) [0|255] ""  ADD
 SG_ VehSysFltWarnSigGrpCntr : 195|4@0+ (1,0) [0|15] ""  ADD

BO_ 188 FZCU_ChassisFusion_0xBC: 64 Vector__XXX
 SG_ FrntMotCtrlSigGrpChks : 23|8@0+ (1,0) [0|255] ""  ADD
 SG_ FrntMotCtrlSigGrpCntr : 27|4@0+ (1,0) [0|15] ""  ADD
 SG_ ReMotCtrlSigGrpChks : 135|8@0+ (1,0) [0|255] ""  ADD
 SG_ ReMotCtrlSigGrpCntr : 139|4@0+ (1,0) [0|15] ""  ADD
 SG_ SuspRoadConditionForADD : 399|8@0+ (1,0) [0|255] ""  ADD
 SG_ VCUFrntDesTqWoIntv : 39|15@0+ (1,-16383) [-16383|16384] "Nm"  ADD
 SG_ VCUFrntDesTqWoIntvVld : 40|1@0+ (1,0) [0|1] ""  ADD
 SG_ VCUFrntMotActSpd : 55|16@0+ (1,-32767) [-32767|32768] "rpm"  ADD
 SG_ VCUFrntMotActSpdVld : 72|1@0+ (1,0) [0|1] ""  ADD
 SG_ VCUFrntMotActTq : 71|15@0+ (1,-16383) [-16383|16384] "Nm"  ADD
 SG_ VCUFrntMotActTqVld : 88|1@0+ (1,0) [0|1] ""  ADD
 SG_ VCUFrntMotWhlTqReq : 87|15@0+ (1,-16383) [-16383|16383] "Nm"  ADD
 SG_ VCUFrntMotWhlTqReqVld : 104|1@0+ (1,0) [0|1] ""  ADD
 SG_ VCUFrntWhlTqMaxAvl : 103|14@0+ (1,0) [0|16383] "Nm"  ADD
 SG_ VCUFrntWhlTqMaxAvlVld : 105|1@0+ (1,0) [0|1] ""  ADD
 SG_ VCUFrntWhlTqMinAvl : 119|14@0+ (1,-16383) [-16383|0] "Nm"  ADD
 SG_ VCUFrntWhlTqMinAvlVld : 121|1@0+ (1,0) [0|1] ""  ADD
 SG_ VCUReDesTqWoIntv : 167|15@0+ (1,-16383) [-16383|16384] "Nm"  ADD
 SG_ VCUReDesTqWoIntvVld : 168|1@0+ (1,0) [0|1] ""  ADD
 SG_ VCUReMotActSpd : 183|16@0+ (1,-32767) [-32767|32768] "rpm"  ADD
 SG_ VCUReMotActSpdVld : 200|1@0+ (1,0) [0|1] ""  ADD
 SG_ VCUReMotActTq : 199|15@0+ (1,-16383) [-16383|16384] "Nm"  ADD
 SG_ VCUReMotActTqVld : 216|1@0+ (1,0) [0|1] ""  ADD
 SG_ VCUReMotWhlTqReq : 215|15@0+ (1,-16383) [-16383|16383] "Nm"  ADD
 SG_ VCUReMotWhlTqReqVld : 233|1@0+ (1,0) [0|1] ""  ADD
 SG_ VCUReWhlTqMaxAvl : 231|14@0+ (1,0) [0|16383] "Nm"  ADD
 SG_ VCUReWhlTqMaxAvlVld : 232|1@0+ (1,0) [0|1] ""  ADD
 SG_ VCUReWhlTqMinAvl : 151|14@0+ (1,-16383) [-16383|0] "Nm"  ADD
 SG_ VCUReWhlTqMinAvlVld : 153|1@0+ (1,0) [0|1] ""  ADD
 SG_ VCUWhlTqMaxAvl : 311|15@0+ (1,0) [0|32767] "N.m"  ADD
 SG_ VCUWhlTqMaxAvlVld : 312|1@0+ (1,0) [0|1] ""  ADD
 SG_ VDMLgtWhlSpdFL : 425|10@0+ (0.1,0) [0|100] "mps"  ADD
 SG_ VDMLgtWhlSpdFR : 447|10@0+ (0.1,0) [0|100] "mps"  ADD
 SG_ VDMLgtWhlSpdRL : 449|10@0+ (0.1,0) [0|100] "mps"  ADD
 SG_ VDMLgtWhlSpdRR : 471|10@0+ (0.1,0) [0|100] "mps"  ADD
 SG_ VDMVehSpdEstmGrpChks : 407|8@0+ (1,0) [0|255] ""  ADD
 SG_ VDMVehSpdEstmGrpCntr : 411|4@0+ (1,0) [0|15] ""  ADD
 SG_ VehBodySideSlipAng : 475|12@0+ (0.01,-6) [-6|6] "deg"  ADD
 SG_ VehLatSpdEstd : 495|10@0+ (0.1,0) [0|100] "m/s"  ADD
 SG_ VehLatSpdEstdVld : 501|1@0+ (1,0) [0|1] ""  ADD
 SG_ VehLgtSpdEstd : 423|10@0+ (0.1,0) [0|100] "m/s"  ADD
 SG_ VehLgtSpdEstdVld : 429|1@0+ (1,0) [0|1] ""  ADD

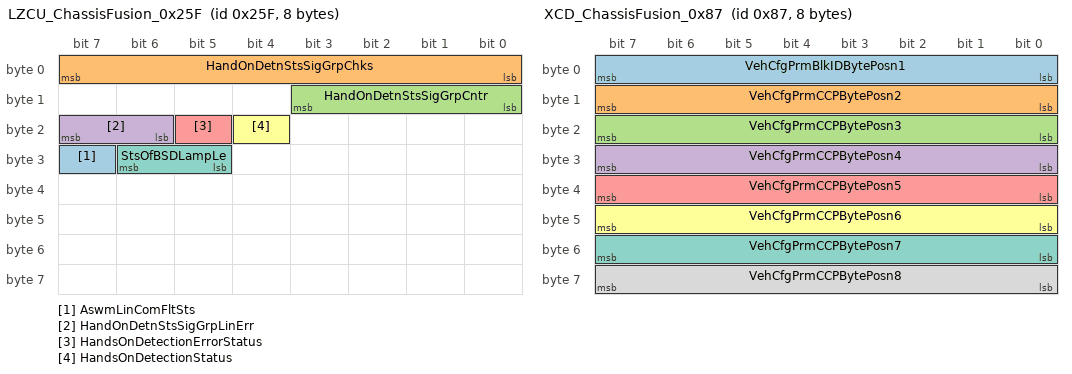
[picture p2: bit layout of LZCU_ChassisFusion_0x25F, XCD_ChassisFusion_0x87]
BO_ 607 LZCU_ChassisFusion_0x25F: 8 Vector__XXX
 SG_ AswmLinComFltSts : 31|1@0+ (1,0) [0|1] ""  ADD
 SG_ HandOnDetnStsSigGrpChks : 7|8@0+ (1,0) [0|255] ""  ADD
 SG_ HandOnDetnStsSigGrpCntr : 11|4@0+ (1,0) [0|15] ""  ADD
 SG_ HandOnDetnStsSigGrpLinErr : 23|2@0+ (1,0) [0|3] ""  ADD
 SG_ HandsOnDetectionErrorStatus : 21|1@0+ (1,0) [0|1] ""  ADD
 SG_ HandsOnDetectionStatus : 20|1@0+ (1,0) [0|1] ""  ADD
 SG_ StsOfBSDLampLe : 30|2@0+ (1,0) [0|3] ""  ADD

BO_ 892 LZCU_ChassisFusion_0x37C: 32 Vector__XXX
 SG_ DrvrOcupcySts : 23|2@0+ (1,0) [0|3] ""  ADD
 SG_ DrvrOcupcyStsGroupChks : 7|8@0+ (1,0) [0|255] ""  ADD
 SG_ DrvrOcupcyStsGroupCntr : 11|4@0+ (1,0) [0|15] ""  ADD

BO_ 616 RZCU_ChassisFusion_0x268: 24 Vector__XXX
 SG_ RlsAutWinWipgSpdCmd : 23|3@0+ (1,0) [0|7] ""  ADD
 SG_ RlsAutWinWipgSpdCmdSigGrpChks : 7|8@0+ (1,0) [0|255] ""  ADD
 SG_ RlsAutWinWipgSpdCmdSigGrpCntr : 11|4@0+ (1,0) [0|15] ""  ADD
 SG_ RlsFwdLiSnsrVal : 47|15@0+ (6,0) [0|196602] ""  ADD
 SG_ RlsFwdLiSnsrValUnit : 87|2@0+ (1,0) [0|3] ""  ADD
 SG_ RlsHudSnsrVal : 63|15@0+ (6,0) [0|196602] ""  ADD
 SG_ RlsHudSnsrValUnit : 85|2@0+ (1,0) [0|3] ""  ADD
 SG_ RlsIRVal : 79|8@0+ (400,0) [0|101600] ""  ADD
 SG_ RlsLiSig1GrpChks : 31|8@0+ (1,0) [0|255] ""  ADD
 SG_ RlsLiSig1GrpCntr : 35|4@0+ (1,0) [0|15] ""  ADD
 SG_ RlsLiSig2GrpChks : 95|8@0+ (1,0) [0|255] ""  ADD
 SG_ RlsLiSig2GrpCntr : 99|4@0+ (1,0) [0|15] ""  ADD
 SG_ RlsLiSigGrpLinErr : 111|2@0+ (1,0) [0|3] ""  ADD
 SG_ RlsLiSnsrFwdFlt : 83|1@0+ (1,0) [0|1] ""  ADD
 SG_ RlsLiSnsrIRFlt : 82|1@0+ (1,0) [0|1] ""  ADD
 SG_ RlsLiSnsrTopFlt : 81|1@0+ (1,0) [0|1] ""  ADD
 SG_ RlsLiSwtReq : 109|2@0+ (1,0) [0|3] ""  ADD
 SG_ RlsOutdBriSts : 107|3@0+ (1,0) [0|7] ""  ADD
 SG_ RlsSts : 135|3@0+ (1,0) [0|7] ""  ADD
 SG_ RlsTopLiSnsrVal : 119|15@0+ (20,0) [0|655340] ""  ADD
 SG_ RlsTopLiSnsrValUnit : 132|2@0+ (1,0) [0|3] ""  ADD
 SG_ StsOfBSDLampRi : 149|2@0+ (1,0) [0|3] ""  ADD

BO_ 893 RZCU_ChassisFusion_0x37D: 8 Vector__XXX
 SG_ PassOcupcySts : 1|2@0+ (1,0) [0|3] ""  ADD

BO_ 342 SCU_ChassisFusion_0x156: 32 Vector__XXX
 SG_ ASCFltSts : 207|2@0+ (1,0) [0|3] ""  ADD
 SG_ CDCFltSts : 205|2@0+ (1,0) [0|3] ""  ADD
 SG_ CurDampgCtrlMod : 124|2@0+ (1,0) [0|3] ""  ADD
 SG_ ESPEnaReq : 203|1@0+ (1,0) [0|1] ""  ADD
 SG_ JackModSts : 113|1@0+ (1,0) [0|1] ""  ADD
 SG_ LvlAdjmtSts : 91|4@0+ (1,0) [0|15] ""  ADD
 SG_ LvlModAct : 135|3@0+ (1,0) [0|7] ""  ADD
 SG_ SCUExtmHeiSts : 202|2@0+ (1,0) [0|3] ""  ADD
 SG_ SCULimSpdTqReq : 215|1@0+ (1,0) [0|1] ""  ADD
 SG_ SCUWarnLampReq : 214|2@0+ (1,0) [0|3] ""  ADD
 SG_ SCUWarnMsgASC : 212|3@0+ (1,0) [0|7] ""  ADD
 SG_ SCUWarnMsgCDC : 209|2@0+ (1,0) [0|3] ""  ADD
 SG_ SCUWarnSigGrpChks : 191|8@0+ (1,0) [0|255] ""  ADD
 SG_ SCUWarnSigGrpCntr : 195|4@0+ (1,0) [0|15] ""  ADD

BO_ 345 XCD_ChassisFusion_0x159: 8 Vector__XXX
 SG_ DiagcExtActv : 6|1@0+ (1,0) [0|1] ""  ADD

BO_ 529 XCD_ChassisFusion_0x211: 16 Vector__XXX
 SG_ SecOCMAC1 : 47|32@0+ (1,0) [0|4294967295] ""  ADD
 SG_ SecOCMAC2 : 79|32@0+ (1,0) [0|4294967295] ""  ADD
 SG_ SecOCMAC3 : 111|24@0+ (1,0) [0|16777215] ""  ADD
 SG_ SecOCResetCnt : 31|16@0+ (1,0) [0|65535] ""  ADD
 SG_ SecOCTripCnt : 7|24@0+ (1,0) [0|16777215] ""  ADD

BO_ 549 XCD_ChassisFusion_0x225: 16 Vector__XXX
 SG_ ADSELKSwtSet : 46|2@0+ (1,0) [0|3] ""  ADD
 SG_ ADSFltQuitReqFrmDCD : 44|2@0+ (1,0) [0|3] ""  ADD
 SG_ DCDAvmCamE2ESigGrpChks : 55|8@0+ (1,0) [0|255] ""  ADD
 SG_ DCDAvmCamE2ESigGrpCntr : 59|4@0+ (1,0) [0|15] ""  ADD
 SG_ DCDAvmFrCamSts : 62|3@0+ (1,0) [0|7] ""  ADD
 SG_ DCDAvmLeCamSts : 71|3@0+ (1,0) [0|7] ""  ADD
 SG_ DCDAvmReCamSts : 68|3@0+ (1,0) [0|7] ""  ADD
 SG_ DCDAvmRiCamSts : 79|3@0+ (1,0) [0|7] ""  ADD
 SG_ DCDDisplayFailSts : 42|3@0+ (1,0) [0|7] ""  ADD
 SG_ DCDDltAllKeyCmdFV : 87|16@0+ (1,0) [0|65535] ""  ADD
 SG_ DCDDltAllKeyCmdMAC : 103|32@0+ (1,0) [0|0] ""  ADD

BO_ 1023 XCD_ChassisFusion_0x3FF: 16 Vector__XXX
 SG_ VidBlkId : 71|8@0+ (1,0) [0|255] ""  ADD
 SG_ VidSignalPos1 : 79|8@0+ (1,0) [0|255] ""  ADD
 SG_ VidSignalPos2 : 87|8@0+ (1,0) [0|255] ""  ADD
 SG_ VidSignalPos3 : 95|8@0+ (1,0) [0|255] ""  ADD
 SG_ VidSignalPos4 : 103|8@0+ (1,0) [0|255] ""  ADD
 SG_ VidSignalPos5 : 111|8@0+ (1,0) [0|255] ""  ADD
 SG_ VidSignalPos6 : 119|8@0+ (1,0) [0|255] ""  ADD
 SG_ VidSignalPos7 : 127|8@0+ (1,0) [0|255] ""  ADD
 SG_ VinVINBlkID : 7|8@0+ (1,0) [0|255] ""  ADD
 SG_ VinVINSignalPos1 : 15|8@0+ (1,0) [0|255] ""  ADD
 SG_ VinVINSignalPos2 : 23|8@0+ (1,0) [0|255] ""  ADD
 SG_ VinVINSignalPos3 : 31|8@0+ (1,0) [0|255] ""  ADD
 SG_ VinVINSignalPos4 : 39|8@0+ (1,0) [0|255] ""  ADD
 SG_ VinVINSignalPos5 : 47|8@0+ (1,0) [0|255] ""  ADD
 SG_ VinVINSignalPos6 : 55|8@0+ (1,0) [0|255] ""  ADD
 SG_ VinVINSignalPos7 : 63|8@0+ (1,0) [0|255] ""  ADD

BO_ 135 XCD_ChassisFusion_0x87: 8 Vector__XXX
 SG_ VehCfgPrmBlkIDBytePosn1 : 7|8@0+ (1,0) [0|150] ""  ADD
 SG_ VehCfgPrmCCPBytePosn2 : 15|8@0+ (1,0) [0|255] ""  ADD
 SG_ VehCfgPrmCCPBytePosn3 : 23|8@0+ (1,0) [0|255] ""  ADD
 SG_ VehCfgPrmCCPBytePosn4 : 31|8@0+ (1,0) [0|255] ""  ADD
 SG_ VehCfgPrmCCPBytePosn5 : 39|8@0+ (1,0) [0|255] ""  ADD
 SG_ VehCfgPrmCCPBytePosn6 : 47|8@0+ (1,0) [0|255] ""  ADD
 SG_ VehCfgPrmCCPBytePosn7 : 55|8@0+ (1,0) [0|255] ""  ADD
 SG_ VehCfgPrmCCPBytePosn8 : 63|8@0+ (1,0) [0|255] ""  ADD

BO_ 389 XCD_ChassisFusion_RT_0x185: 16 Vector__XXX
 SG_ AdasSwt : 23|2@0+ (1,0) [0|3] ""  ADD
 SG_ AdasSwtSigGrpChks : 7|8@0+ (1,0) [0|255] ""  ADD
 SG_ AdasSwtSigGrpCntr : 11|4@0+ (1,0) [0|15] ""  ADD
 SG_ AdasSwtSigGrpLinErr : 21|2@0+ (1,0) [0|3] ""  ADD
 SG_ HoodOpenClsSts : 51|2@0+ (1,0) [0|3] ""  ADD
 SG_ LeKnobCounter : 39|8@0+ (1,0) [0|254] ""  ADD
 SG_ LeKnobRotDir : 47|2@0+ (1,0) [0|3] ""  ADD
 SG_ LeMFctActSgCe : 45|2@0+ (1,0) [0|3] ""  ADD
 SG_ LeMFctActSgLe : 43|2@0+ (1,0) [0|3] ""  ADD
 SG_ LeMFctActSgRi : 41|2@0+ (1,0) [0|3] ""  ADD
 SG_ RiMFctActSgCe : 55|2@0+ (1,0) [0|3] ""  ADD
 SG_ TrOpenClsSts : 71|2@0+ (1,0) [0|3] ""  ADD

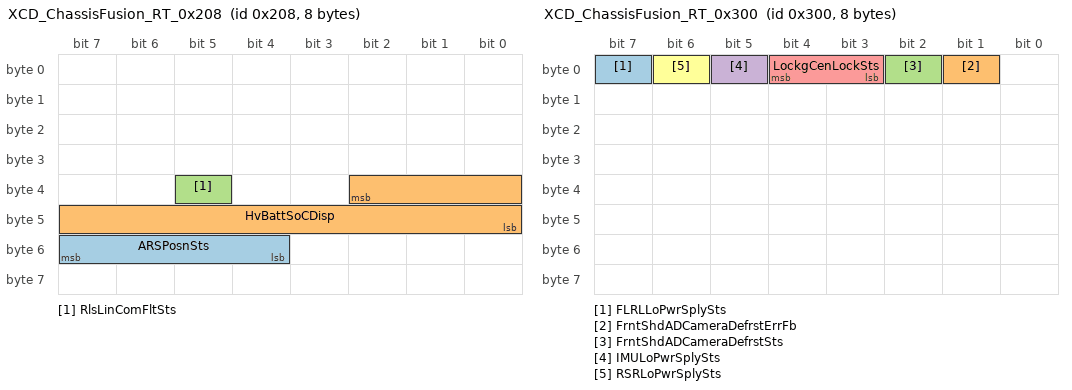
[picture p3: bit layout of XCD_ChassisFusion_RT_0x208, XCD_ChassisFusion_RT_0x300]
BO_ 520 XCD_ChassisFusion_RT_0x208: 8 Vector__XXX
 SG_ ARSPosnSts : 55|4@0+ (1,0) [0|15] ""  ADD
 SG_ HvBattSoCDisp : 34|11@0+ (0.05,0) [0|100] "%"  ADD
 SG_ RlsLinComFltSts : 37|1@0+ (1,0) [0|1] ""  ADD

BO_ 768 XCD_ChassisFusion_RT_0x300: 8 Vector__XXX
 SG_ FLRLLoPwrSplySts : 7|1@0+ (1,0) [0|1] ""  ADD
 SG_ FrntShdADCameraDefrstErrFb : 1|1@0+ (1,0) [0|1] ""  ADD
 SG_ FrntShdADCameraDefrstSts : 2|1@0+ (1,0) [0|1] ""  ADD
 SG_ IMULoPwrSplySts : 5|1@0+ (1,0) [0|1] ""  ADD
 SG_ LockgCenLockSts : 4|2@0+ (1,0) [0|3] ""  ADD
 SG_ RSRLoPwrSplySts : 6|1@0+ (1,0) [0|1] ""  ADD

BO_ 1313 XCDChassisFusionNMFr: 8 Vector__XXX
 SG_ NMKeepAwkRsnVCCD : 48|9@0+ (1,0) [0|511] ""  ADD
 SG_ UDB17VCCD : 17|1@0+ (1,0) [0|1] ""  ADD
 SG_ UDB18VCCD : 18|1@0+ (1,0) [0|1] ""  ADD
 SG_ UDB19VCCD : 19|1@0+ (1,0) [0|1] ""  ADD
 SG_ UDB20VCCD : 20|1@0+ (1,0) [0|1] ""  ADD
 SG_ UDB21VCCD : 21|1@0+ (1,0) [0|1] ""  ADD
 SG_ UDB22VCCD : 22|1@0+ (1,0) [0|1] ""  ADD
 SG_ UDB23VCCD : 23|1@0+ (1,0) [0|1] ""  ADD
 SG_ UDB24VCCD : 24|1@0+ (1,0) [0|1] ""  ADD
 SG_ UDB25VCCD : 25|1@0+ (1,0) [0|1] ""  ADD
 SG_ UDB26VCCD : 26|1@0+ (1,0) [0|1] ""  ADD
 SG_ UDB27VCCD : 27|1@0+ (1,0) [0|1] ""  ADD
 SG_ UDB28VCCD : 28|1@0+ (1,0) [0|1] ""  ADD
 SG_ UDB29VCCD : 29|1@0+ (1,0) [0|1] ""  ADD
 SG_ UDB30VCCD : 30|1@0+ (1,0) [0|1] ""  ADD
 SG_ UDB31VCCD : 31|1@0+ (1,0) [0|1] ""  ADD
 SG_ UDB32VCCD : 32|1@0+ (1,0) [0|1] ""  ADD
 SG_ UDB33VCCD : 33|1@0+ (1,0) [0|1] ""  ADD
 SG_ UDB34VCCD : 34|1@0+ (1,0) [0|1] ""  ADD
 SG_ UDB35VCCD : 35|1@0+ (1,0) [0|1] ""  ADD
 SG_ UDB36VCCD : 36|1@0+ (1,0) [0|1] ""  ADD
 SG_ UDB37VCCD : 37|1@0+ (1,0) [0|1] ""  ADD
 SG_ UDB38VCCD : 38|1@0+ (1,0) [0|1] ""  ADD
 SG_ UDB39VCCD : 39|1@0+ (1,0) [0|1] ""  ADD
 SG_ UDB40VCCD : 40|1@0+ (1,0) [0|1] ""  ADD
 SG_ UDB41VCCD : 41|1@0+ (1,0) [0|1] ""  ADD
 SG_ UDB42VCCD : 42|1@0+ (1,0) [0|1] ""  ADD
 SG_ UDB43VCCD : 43|1@0+ (1,0) [0|1] ""  ADD
 SG_ UDB44VCCD : 44|1@0+ (1,0) [0|1] ""  ADD
 SG_ UDB45VCCD : 45|1@0+ (1,0) [0|1] ""  ADD
 SG_ UDB46VCCD : 46|1@0+ (1,0) [0|1] ""  ADD
 SG_ UDB47VCCD : 47|1@0+ (1,0) [0|1] ""  ADD
 SG_ UDB49VCCD : 49|1@0+ (1,0) [0|1] ""  ADD
 SG_ UDB50VCCD : 50|1@0+ (1,0) [0|1] ""  ADD
 SG_ UDB51VCCD : 51|1@0+ (1,0) [0|1] ""  ADD
 SG_ UDB52VCCD : 52|1@0+ (1,0) [0|1] ""  ADD
 SG_ UDB53VCCD : 53|1@0+ (1,0) [0|1] ""  ADD
 SG_ VCCDChassisBkpActiveWakeup : 12|1@0+ (1,0) [0|1] ""  ADD
 SG_ VCCDChassisBkpNodeAddress : 7|8@0+ (1,0) [0|255] ""  ADD
 SG_ VCCDChassisBkpRepeatMsgReq : 8|1@0+ (1,0) [0|1] ""  ADD
 SG_ VCCDChassisBkpRepeatMsgSt : 16|1@0+ (1,0) [0|1] ""  ADD

CM_ SG_ 688 ADDCooltFlowReqFrmADD "ADD coolant flowrate Request";
CM_ SG_ 688 ADDFaultInfoFlag "ADD Fault Information Flag";
CM_ SG_ 688 ADDTValFrmADD "ADD Temperature Value";
CM_ SG_ 688 ADSLrnUnavlRsnFrmADD "1";
CM_ SG_ 688 ADSParkSpdSwtStsFrmADD "Adas parking speed switch status
泊车速度开关状态";
CM_ SG_ 688 ADSParkSpdSwtUnavlRsnFrmADD "Adas parking speed switch unavailable reason  泊车速度开关不可点击原因";
CM_ SG_ 688 APASwtStsFrmADD "APA Switch Status";
CM_ SG_ 688 APASwtUnavlRsnFrmADD "APA Switch Unavailable Reason
APA 开关不可点击原因反馈信号";
CM_ SG_ 688 AutoVehCustEIPSwtFrmADD "智能驾驶用户体验改进计划开关  Autonomous Vehicle Customer Experience Improvement Program Switch";
CM_ SG_ 688 AutoVehCustEIPSwtRsnFrmADD "智能驾驶用户体验改进计划开关不可用原因";
CM_ SG_ 688 AutoVehSrvAuthntStsFrmADD "智能驾驶服务授权状态
Autonomous Vehicle Service Authorization Status";
CM_ SG_ 688 AutoVehSrvAuthntStsRsnFrmADD "智能驾驶服务授权不可用原因";
CM_ SG_ 688 AvmCamTriggerModReqFrmADD "AVM环视相机帧同步切换请求";
CM_ SG_ 688 AVPSwtStsFrmADD "AVP Switch Status
AVP 泊车设置项开关";
CM_ SG_ 688 AVPSwtUnavlRsnFrmADD "AVP Switch Unavailable Reason
AVP开关不可点击原因反馈信号";
CM_ SG_ 688 HPPBckGrLearFrmADD "HPP Background learning Switch Status
HPP后台自学习设置项开关";
CM_ SG_ 688 HPPBckGrLearUnavlRsnFrmADD "HPP BackGround Learning Unavailable Reason
HPP后台自学习开关不可点原因";
CM_ SG_ 688 HPPSwtStsFrmADD "HPP Switch Status
HPP主设置项开关";
CM_ SG_ 688 HPPSwtUnavlRsnFrmADD "HPP Switch Unavailable Reason
HPP开关不可点击原因反馈信号";
CM_ SG_ 688 RPASentryQuit "RPA退出哨兵模式请求";
CM_ SG_ 693 ParkOutTarDirFrmADD "Park Out Target Direction
目标泊出方向";
CM_ SG_ 693 ParkSlotTarFrmADD "Target Park Slot
目标车位";
CM_ SG_ 693 PASBuzzerWarnMuteReqFrmADD "Mute PAS Buzzer alarm Request
静音PAS声音报警请求";
CM_ SG_ 693 PASFCBuzzerWarnFrmADD "PAS Front Center Buzzer alarm level
PAS前中区声音报警信号";
CM_ SG_ 693 PASFLBuzzerWarnFrmADD "PAS Front Left Buzzer alarm level
PAS前左区声音报警信号";
CM_ SG_ 693 PASFLDistanceFrmADD "Front Left area distance display
倒车雷达左前区距离显示";
CM_ SG_ 693 PASFLDistanceLevFrmADD "Front Left area distance  Level 
倒车雷达左前区距离显示等级";
CM_ SG_ 693 PASFMLDistanceFrmADD "Front middle Left area distance display
倒车雷达左中前区距离显示";
CM_ SG_ 693 PASFMLDistanceLevFrmADD "Front middle Left area distance Level
倒车雷达左中前区距离显示等级";
CM_ SG_ 693 PASFMRDistanceFrmADD "Front Middle Right area distance display
倒车雷达右中前区距离显示";
CM_ SG_ 693 PASFMRDistanceLevFrmADD "Front Middle Right area distance Level
倒车雷达右中前区距离显示等级";
CM_ SG_ 693 PASFRBuzzerWarnFrmADD "PAS Front Right Buzzer alarm level
PAS前右区声音报警信号";
CM_ SG_ 693 PASFRDistanceFrmADD "Front Right area distance display
倒车雷达右前区距离显示";
CM_ SG_ 693 PASFRDistanceLevFrmADD "Front Right area distance Level
倒车雷达右前区距离显示等级";
CM_ SG_ 693 PASFSLDistanceFrmADD "Front Side Left area distance display
 倒车雷达前左侧区距离显示";
CM_ SG_ 693 PASFSLDistanceLevFrmADD "Front Side Left area distance  Level 
倒车雷达前左侧区距离显示等级";
CM_ SG_ 693 PASFSRDistanceFrmADD "Front Side Right area distance display
倒车雷达前右侧区距离显示";
CM_ SG_ 693 PASFSRDistanceLevFrmADD "Front Side Right area distance  Level 
倒车雷达前右侧区距离显示等级";
CM_ SG_ 693 PASRLBuzzerWarnFrmADD "PAS Rear Left Buzzer alarm level
PAS后左区声音报警信号";
CM_ SG_ 693 PASRLDistanceFrmADD "Rear Left area distance display
倒车雷达左后区距离显示";
CM_ SG_ 693 PASRLDistanceLevFrmADD "Rear Left area distance Level
倒车雷达左后区距离显示等级";
CM_ SG_ 693 PASRMLDistanceFrmADD "Rear Middle Left area distance display
倒车雷达左中后区距离显示";
CM_ SG_ 693 PASRMLDistanceLevFrmADD "Rear Middle Left area distance Level
倒车雷达左中后区距离显示等级";
CM_ SG_ 693 PASRMRDistanceFrmADD "Rear Middle Right area distance display 
倒车雷达右中后区距离显示";
CM_ SG_ 693 PASRMRDistanceLevFrmADD "Rear Middle Right area distance Level 
倒车雷达右中后区距离显示等级";
CM_ SG_ 693 PASRRBuzzerWarnFrmADD "PAS Rear Right Buzzer alarm level
PAS后右区声音报警信号";
CM_ SG_ 693 PASRRDistanceFrmADD "Rear Right area distance display
倒车雷达右后区距离显示";
CM_ SG_ 693 PASRRDistanceLevFrmADD "Rear Right area distance Level
倒车雷达右后区距离显示等级";
CM_ SG_ 693 PASRSLDistanceFrmADD "Rear Side Left area distance display 
倒车雷达后左侧区距离显示";
CM_ SG_ 693 PASRSLDistanceLevFrmADD "Rear Side Left area distance  Level 
倒车雷达后左侧区距离显示等级";
CM_ SG_ 693 PASRSRDistanceFrmADD "Rear Side Right area distance display  
倒车雷达后右侧区距离显示";
CM_ SG_ 693 PASRSRDistanceLevFrmADD "Rear Side Right area distance  Level 
倒车雷达后右侧区距离显示等级";
CM_ SG_ 693 PASSDWFLSideDistanceFrmADD "Front Left side area distance display
左前侧边障碍物距离";
CM_ SG_ 693 PASSDWFLSideDistanceLevFrmADD "Front Left side area distance Level
左前侧边障碍物距离显示等级";
CM_ SG_ 693 PASSDWFMLSideDistanceFrmADD "Front Middle Left side area distance display
左中前障碍物距离";
CM_ SG_ 693 PASSDWFMLSideDistanceLevFrmADD "Front Middle Left side area distance Level
左中前障碍物距离显示等级";
CM_ SG_ 693 PASSDWFMRSideDistanceFrmADD "Front Middle Right side area distance display
右中前障碍物距离";
CM_ SG_ 693 PASSDWFMRSideDistanceLevFrmADD "Front Middle Right side area distance Level
右中前障碍物距离显示等级";
CM_ SG_ 693 PASSDWFRSideDistanceFrmADD "Front Right side area distance display
右前侧边障碍物距离";
CM_ SG_ 693 PASSDWFRSideDistanceLevFrmADD "Front Right side area distance Level
右前侧边障碍物距离显示等级";
CM_ SG_ 693 PASSDWRLSideDistanceFrmADD "Rear Left side area distance display
左后侧边障碍物距离";
CM_ SG_ 693 PASSDWRLSideDistanceLevFrmADD "Rear Left side area distance Level
左后侧边障碍物距离显示等级";
CM_ SG_ 693 PASSDWRMLSideDistanceFrmADD "Rear Middle Left side area distance display
左中后障碍物距离";
CM_ SG_ 693 PASSDWRMLSideDistanceLevFrmADD "Rear Middle Left side area distance display
左中后障碍物距离显示等级";
CM_ SG_ 693 PASSDWRMRSideDistanceFrmADD "Rear Middle Right side area distance display
右中后障碍物距离";
CM_ SG_ 693 PASSDWRMRSideDistanceLevFrmADD "Rear Middle Right side area distance Level
右中后障碍物距离显示等级";
CM_ SG_ 693 PASSDWRRSideDistanceFrmADD "Rear Right side area distance display
右后侧边障碍物距离";
CM_ SG_ 693 PASSDWRRSideDistanceLevFrmADD "Rear Right side area distance Level
右后侧边障碍物距离显示等级";
CM_ SG_ 775 ParkProgressSigLFPosXFrmADD "Parking Progress Left Front Position X
预期单步泊车位置左前角点横坐标";
CM_ SG_ 775 ParkProgressSigLFPosYFrmADD "Parking Progress Left Front Position Y
预期单步泊车位置左前角点纵坐标";
CM_ SG_ 775 ParkProgressSigLRPosXFrmADD "Parking Progress Left Rear Position X
预期单步泊车位置左后角点横坐标";
CM_ SG_ 775 ParkProgressSigLRPosYFrmADD "Parking Progress Left Rear Position Y
预期单步泊车位置左后角点纵坐标";
CM_ SG_ 775 ParkProgressSigRFPosXFrmADD "Parking Progress Right Front Position X
预期单步泊车位置右前角点横坐标";
CM_ SG_ 775 ParkProgressSigRFPosYFrmADD "Parking Progress Right Front Position Y
预期单步泊车位置右前角点纵坐标";
CM_ SG_ 775 ParkProgressSigRRPosXFrmADD "Parking Progress Right Rear Position X
预期单步泊车位置右后角点横坐标";
CM_ SG_ 775 ParkProgressSigRRPosYFrmADD "Parking Progress Right Rear Position Y
预期单步泊车位置右后角点纵坐标";
CM_ SG_ 775 PASSubFunAvaiFrmADD "PAS Subsystem Function Available 
PAS子系统状态";
CM_ SG_ 775 PASWorkingModeFrmADD "PAS Working mode of reversing radar
倒车雷达的工作模式";
CM_ SG_ 873 LowPwrReqFrLdrFrmADD "ADD发送的管理激光雷达供电的请求信号";
CM_ SG_ 873 LowPwrReqFrRdrFrmADD "ADD发送的管理毫米波雷达供电的请求信号";
CM_ SG_ 238 ADD2BLEMForRPA00 "RPA路由功能";
CM_ SG_ 238 ADD2BLEMForRPA01 "RPA路由功能";
CM_ SG_ 238 ADD2BLEMForRPA02 "RPA路由功能";
CM_ SG_ 238 ADD2BLEMForRPA03 "RPA路由功能";
CM_ SG_ 239 XAccelStaFrmADD "IMUx轴加速度状态位 0正常 1功能安全异常 2超量程 3无效数值";
CM_ SG_ 239 XAccelValFrmADD "IMUx轴加速度，m/s^2
[-10g,10g], g:9.81";
CM_ SG_ 239 XAngRateStaFrmADD "IMUx轴角速度状态位 0正常 1功能安全异常 2超量程 3无效数值";
CM_ SG_ 239 XAngRateValFrmADD "'IMUx轴角速率，rad/s
[-500°/s，500°/s],pi:3.1415926'
";
CM_ SG_ 239 YAccelStaFrmADD "IMUy轴加速度状态位 0正常 1功能安全异常 2超量程 3无效数值";
CM_ SG_ 239 YAccelValFrmADD "IMUy轴加速度 m s^2
  10g 10g  g 9.81";
CM_ SG_ 239 YAngRateStaFrmADD "IMUy轴角速度状态位 0正常 1功能安全异常 2超量程 3无效数值";
CM_ SG_ 239 YAngRateValFrmADD "IMUy轴角速率 rad s
  500 s 500 s  pi 3.1415926";
CM_ SG_ 239 ZAccelStaFrmADD "IMUz轴加速度状态位 0正常 1功能安全异常 2超量程 3无效数值";
CM_ SG_ 239 ZAccelValFrmADD "IMUz轴加速度 m s^2
  10g 10g  g 9.81";
CM_ SG_ 239 ZAngRateStaFrmADD "IMUz轴角速度状态位 0正常 1功能安全异常 2超量程 3无效数值";
CM_ SG_ 239 ZAngRateValFrmADD "IMUz轴角速率 rad s
  500 s 500 s  pi 3.1415926";
CM_ SG_ 1331 ADDChassisBkpActiveWakeup "Active Wakeup Bit";
CM_ SG_ 1331 ADDChassisBkpNodeAddress "Node source address";
CM_ SG_ 1331 ADDChassisBkpRepeatMsgReq "Repeat Message Request Bit";
CM_ SG_ 1331 ADDChassisBkpRepeatMsgSt "Repeat Message State indication";
CM_ SG_ 1326 ADDChassisBkpActiveWakeup1 "Active Wakeup Bit";
CM_ SG_ 1326 ADDChassisBkpNodeAddress1 "Node source address";
CM_ SG_ 1326 ADDChassisBkpRepeatMsgReq1 "Repeat Message Request Bit";
CM_ SG_ 1326 ADDChassisBkpRepeatMsgSt1 "Repeat Message State indication";
CM_ SG_ 487 BrkSysBrkPedlAppld "Indicates whether the driver operates the
brakepedal.Only active when the driver brakes";
CM_ SG_ 487 BrkSysBrkPedlAppldVld "Qualifier for brake system brake pedal applied signal";
CM_ SG_ 487 BrkSysEnaActvCtrlByDrvr "Indicate if the BCP pressure control is dominated by driver";
CM_ SG_ 487 BrkSysFTarDrvr "Target brake force from driver";
CM_ SG_ 487 BrkSysFTarDrvrVld "Qualifier for Target brake force from driver signal";
CM_ SG_ 487 BrkSysPRednPotnl "Indicates the pressure reduction potential from BCP to BCS  to limit the max CRB brakeregen.";
CM_ SG_ 487 BrkSysPRednPotnlVld "Qualifier for pressure reduction potential signal";
CM_ SG_ 487 BrkSysWarnLampReq "Indicatethewarninglampinfothatshouldbeset";
CM_ SG_ 444 RCAvailable "远控设备可用";
CM_ SG_ 444 RPARemReq "遥控泊车APP开关";
CM_ SG_ 657 BLEM2VCCDForLocn10 "BLEM to VCCD For Phone1 location";
CM_ SG_ 657 BLEM2VCCDForLocn11 "BLEM to VCCD For Phone1 location";
CM_ SG_ 657 BLEM2VCCDForLocn12 "BLEM to VCCD For Phone1 location";
CM_ SG_ 657 BLEM2VCCDForLocn13 "BLEM to VCCD For Phone1 location";
CM_ SG_ 657 BLEM2VCCDForLocn14 "BLEM to VCCD For Phone1 location";
CM_ SG_ 657 BLEM2VCCDForLocn15 "BLEM to VCCD For Phone1 location";
CM_ SG_ 657 BLEM2VCCDForLocn16 "BLEM to VCCD For Phone1 location";
CM_ SG_ 657 BLEM2VCCDForLocn17 "BLEM to VCCD For Phone1 location";
CM_ SG_ 657 BLEM2VCCDForLocn18 "BLEM to VCCD For Phone1 location";
CM_ SG_ 657 BLEM2VCCDForLocn19 "BLEM to VCCD For Phone1 location";
CM_ SG_ 657 BLEM2VCCDForLocn1A "BLEM to VCCD For Phone1 location";
CM_ SG_ 657 BLEM2VCCDForLocn1B "BLEM to VCCD For Phone1 location";
CM_ SG_ 657 BLEM2VCCDForLocn1C "BLEM to VCCD For Phone1 location";
CM_ SG_ 657 BLEM2VCCDForLocn1D "BLEM to VCCD For Phone1 location";
CM_ SG_ 657 BLEM2VCCDForLocn1F "BLEM to VCCD For Phone1 location";
CM_ SG_ 663 SndBLEKeyPosnToRPA "Send BLE key message to RPA module";
CM_ SG_ 665 BLEM2VCCDForLocn20 "BLEM to VCCD For Phone2 location";
CM_ SG_ 665 BLEM2VCCDForLocn21 "BLEM to VCCD For Phone2 location";
CM_ SG_ 665 BLEM2VCCDForLocn22 "BLEM to VCCD For Phone2 location";
CM_ SG_ 665 BLEM2VCCDForLocn23 "BLEM to VCCD For Phone2  location";
CM_ SG_ 665 BLEM2VCCDForLocn24 "BLEM to VCCD For Phone2 location";
CM_ SG_ 665 BLEM2VCCDForLocn25 "BLEM to VCCD For Phone2 location";
CM_ SG_ 665 BLEM2VCCDForLocn26 "BLEM to VCCD For Phone2 location";
CM_ SG_ 665 BLEM2VCCDForLocn27 "BLEM to VCCD For Phone2 location";
CM_ SG_ 665 BLEM2VCCDForLocn28 "BLEM to VCCD For Phone2 location";
CM_ SG_ 665 BLEM2VCCDForLocn29 "BLEM to VCCD For Phone2 location";
CM_ SG_ 665 BLEM2VCCDForLocn2A "BLEM to VCCD For Phone2 location";
CM_ SG_ 665 BLEM2VCCDForLocn2B "BLEM to VCCD For Phone2 location";
CM_ SG_ 665 BLEM2VCCDForLocn2C "BLEM to VCCD For Phone2 location";
CM_ SG_ 665 BLEM2VCCDForLocn2D "BLEM to VCCD For Phone2 location";
CM_ SG_ 665 BLEM2VCCDForLocn2F "BLEM to VCCD For Phone2 location";
CM_ SG_ 758 FrntLeTyrePVal "FrontLeftTyrePressureValue";
CM_ SG_ 758 FrntLeTyrePWarn "FrontLeftTyrePressureWarning";
CM_ SG_ 758 FrntRiTyrePVal "FrontRightTyrePressureValue";
CM_ SG_ 758 FrntRiTyrePWarn "FrontRightTyrePressureWarning";
CM_ SG_ 758 ReLeTyrePVal "RearLeftTyrePressureValue";
CM_ SG_ 758 ReLeTyrePWarn "RearLeftTyrePressureWarning";
CM_ SG_ 758 ReRiTyrePVal "RearRightTyrePressureValue";
CM_ SG_ 758 ReRiTyrePWarn "RearRightTyrePressureWarning";
CM_ SG_ 817 BLEM2VCCDForLocn40 "BLEM to VCCD For Phone4 location";
CM_ SG_ 817 BLEM2VCCDForLocn41 "BLEM to VCCD For Phone4 location";
CM_ SG_ 817 BLEM2VCCDForLocn42 "BLEM to VCCD For Phone4 location";
CM_ SG_ 817 BLEM2VCCDForLocn43 "BLEM to VCCD For Phone4 location";
CM_ SG_ 817 BLEM2VCCDForLocn44 "BLEM to VCCD For Phone4 location";
CM_ SG_ 817 BLEM2VCCDForLocn45 "BLEM to VCCD For Phone4 location";
CM_ SG_ 817 BLEM2VCCDForLocn46 "BLEM to VCCD For Phone4 location";
CM_ SG_ 817 BLEM2VCCDForLocn47 "BLEM to VCCD For Phone4 location";
CM_ SG_ 817 BLEM2VCCDForLocn48 "BLEM to VCCD For Phone4 location";
CM_ SG_ 817 BLEM2VCCDForLocn49 "BLEM to VCCD For Phone4 location";
CM_ SG_ 817 BLEM2VCCDForLocn4A "BLEM to VCCD For Phone4 location";
CM_ SG_ 817 BLEM2VCCDForLocn4B "BLEM to VCCD For Phone4 location";
CM_ SG_ 817 BLEM2VCCDForLocn4C "BLEM to VCCD For Phone4 location";
CM_ SG_ 817 BLEM2VCCDForLocn4D "BLEM to VCCD For Phone4 location";
CM_ SG_ 817 BLEM2VCCDForLocn4F "BLEM to VCCD For Phone4 location";
CM_ SG_ 825 BLEM2ADDForRPA00 "RPA路由功能";
CM_ SG_ 825 BLEM2ADDForRPA01 "RPA路由功能";
CM_ SG_ 825 BLEM2ADDForRPA02 "RPA路由功能";
CM_ SG_ 825 BLEM2ADDForRPA03 "RPA路由功能";
CM_ SG_ 826 BLEM2VCCDForLocn30 "BLEM to VCCD For Phone3 location";
CM_ SG_ 826 BLEM2VCCDForLocn31 "BLEM to VCCD For Phone3 location";
CM_ SG_ 826 BLEM2VCCDForLocn32 "BLEM to VCCD For Phone3 location";
CM_ SG_ 826 BLEM2VCCDForLocn33 "BLEM to VCCD For Phone3 location";
CM_ SG_ 826 BLEM2VCCDForLocn34 "BLEM to VCCD For Phone3 location";
CM_ SG_ 826 BLEM2VCCDForLocn35 "BLEM to VCCD For Phone3 location";
CM_ SG_ 826 BLEM2VCCDForLocn36 "BLEM to VCCD For Phone3 location";
CM_ SG_ 826 BLEM2VCCDForLocn37 "BLEM to VCCD For Phone3 location";
CM_ SG_ 826 BLEM2VCCDForLocn38 "BLEM to VCCD For Phone3 location";
CM_ SG_ 826 BLEM2VCCDForLocn39 "BLEM to VCCD For Phone3 location";
CM_ SG_ 826 BLEM2VCCDForLocn3A "BLEM to VCCD For Phone3 location";
CM_ SG_ 826 BLEM2VCCDForLocn3B "BLEM to VCCD For Phone3 location";
CM_ SG_ 826 BLEM2VCCDForLocn3C "BLEM to VCCD For Phone3 location";
CM_ SG_ 826 BLEM2VCCDForLocn3D "BLEM to VCCD For Phone3 location";
CM_ SG_ 826 BLEM2VCCDForLocn3F "BLEM to VCCD For Phone3 location";
CM_ SG_ 827 BLEM2VCCDForRkeReq00 "BLEM发送RKE请求";
CM_ SG_ 827 BLEM2VCCDForRkeReq01 "BLEM发送RKE请求";
CM_ SG_ 827 BLEM2VCCDForRkeReq02 "BLEM发送RKE请求";
CM_ SG_ 827 BLEM2VCCDForRkeReq03 "BLEM发送RKE请求";
CM_ SG_ 827 BLEM2VCCDForRkeReq08 "BLEM发送RKE请求";
CM_ SG_ 827 BLEM2VCCDForRkeReq09 "BLEM发送RKE请求";
CM_ SG_ 827 BLEM2VCCDForRkeReq10 "BLEM发送RKE请求";
CM_ SG_ 827 BLEM2VCCDForRkeReq11 "BLEM发送RKE请求";
CM_ SG_ 827 BLEM2VCCDForRkeReq12 "BLEM发送RKE请求";
CM_ SG_ 827 BLEM2VCCDForRkeReq13 "BLEM发送RKE请求";
CM_ SG_ 827 BLEM2VCCDForRkeReq14 "BLEM发送RKE请求";
CM_ SG_ 581 BattSoh "Battery State of health
电池SOH";
CM_ SG_ 581 BMDMAcvDcnMosSt "BMDM active disconnect Mosfet State
BMDM主动断电Mos状态";
CM_ SG_ 355 AVPHPPCtrlAvlStsBkp "EPS AVP/HPP Feature Control Avaliable Status Back Up
EPS对于 AVP/HPP 功能的控制可用状态备份信号";
CM_ SG_ 355 AVPHPPCtrStsBkp "What channel of the EPS is in control back up.
表征EPS目前正在响应的通道备份信号";
CM_ SG_ 355 AVPHPPReqFbStsBkp "EPS feedback for AVP/HPP request back up
EPS 对于AVP/HPP的请求反馈备份信号";
CM_ SG_ 355 AVPHPPReqFltStsBkp "EPS fault status related to execution of AVP/HPP back up
EPS反馈AVP/HPP当前的故障状态备份信号";
CM_ SG_ 355 FailrStsBkp "EPS 故障状态 备份CAN 
EPS Failure Status
 back up";
CM_ SG_ 994 CcwEOTDetBkp "Bkp CANFD:
Counter Clock wise End of Stop Value Learned Flag. 逆时针软止点(末端)位置学习成功标志位";
CM_ SG_ 994 CcwEOTValueBkp "Bkp CANFD:Counter Clock wise End of Stop Value, Direction:Counter Clock wise is.逆时针软止点(末端)位置, 方向:逆时针为正";
CM_ SG_ 994 CwEOTDetBkp "Bkp CANFD:
Clock wise End of Stop Value Learned Flag. 顺时针软止点(末端)位置学习成功标志位";
CM_ SG_ 994 CwEOTValueBkp "BkpCANFD:Clock wise End of Stop Value, Direction: Clock wise is.顺时针软止点(末端)位置, 方向:顺时针为负";
CM_ SG_ 200 PinionAglSpdBkpV2C "For BkpCAN: Convert VGR Pinion Velocity to CGR Pinion Velocity.用于备份CAN:将VGR方向盘转速转成CGR转速.方向:顺时针为负,逆时针为正";
CM_ SG_ 200 PinionSteerAglBkp "方向盘转角 备份CAN 
Steering Wheel Angle back up
方向  
Anticlockwise direction of steering wheel increase angle output.
Clockwise direction of steering wheel decrease angle output.";
CM_ SG_ 200 PinionSteerAglBkpV2C "For BkpCAN:Convert VGR pinion angle to CGR pinion angle.用于备份CAN:将VGR方向盘转角转成CGR转角";
CM_ SG_ 200 PinionSteerAglSpdBkp "方向盘转速 备份CAN 
Steering Wheel Velocity back up
方向  Clockwise     Anti Clockwise";
CM_ SG_ 200 PinionSteerAglSpdVldBkp "方向盘转速有效位 备份CAN 
Steering Wheel Velocity Valid Flag back up";
CM_ SG_ 200 PinionSteerAglSpdVldBkpV2C "BkpCAN:PinionVelocity Valid Flag.备份CAN:方向盘转速有效位";
CM_ SG_ 200 PinionSteerAglVldBkp "方向盘转角有效位 备份CAN 
Steering Wheel Angle Valid Flag back up";
CM_ SG_ 200 PinionSteerAglVldBkpV2C "BkpCAN: PinionAngle Valid Flag
备份CAN: 方向盘转交有效位";
CM_ SG_ 200 SteerWhlTqBkp "方向盘扭矩 备份CAN 
Steering Wheel Torque back up
方向  Clockwise     Anti Clockwise";
CM_ SG_ 200 SteerWhlTqVldBkp "方向盘扭矩有效位 备份CAN 
Steering Wheel torque Valid Flag back up";
CM_ SG_ 515 VCUExtmPfmncMod "VCU extreme performance mode
VCU狂暴模式";
CM_ SG_ 515 VCUTrlrModStSts "VCU Trailer Mode Setting Status
VCU反馈拖车模式设置状态";
CM_ SG_ 515 VCUWashModStSts "VCU wash mode setting status 
VCU洗车模式设定状态";
CM_ SG_ 515 VDMMueEstdForADD "Road Mue Estimated for ADD
车端感知道路附着系数";
CM_ SG_ 656 ADDCooltCircFlowEstimd "Estimated coolant flowrate for ADD coolant circuit.";
CM_ SG_ 656 AmbTEstimd "Estimated ambient temperature.";
CM_ SG_ 656 AmbTEstimdVld "Estimated ambient temperature valid value.";
CM_ SG_ 656 EdsCircCooltT "Coolant temperature at EDS coolant circuit";
CM_ SG_ 656 EdsCircCooltTSnsrU "Coolant temperature sensor voltage at EDS coolant circuit";
CM_ SG_ 656 EdsCircCooltTVld "Coolant temperature at EDS coolant circuit valid value";
CM_ SG_ 656 LRR2LoPwrSplySts "4D 毫米波雷达配电状态";
CM_ SG_ 656 LRRLoPwrSplySts "LRR low Power Supply Status
前向毫米波雷达配电状态";
CM_ SG_ 656 VCUBattOverHeatWarn "电池过温时 仪表点亮电池过温报警灯";
CM_ SG_ 656 VCUDrvMotFltWarn "当驱动电机发生故障时 仪表点亮驱动电机故障灯";
CM_ SG_ 656 VCUDrvMotOverHeatWarn "驱动电机过热报警";
CM_ SG_ 656 VCUDrvSysLimdWarn "VCU发送点亮跛行故障灯信号 仪表点灯";
CM_ SG_ 656 VCUEgyCnsInCurDrvCyc "显示本次行程的电耗量";
CM_ SG_ 656 VCUEstimdCrsRng "Estimated range
续航里程值显示";
CM_ SG_ 656 VCUEstimdCrsRngForCltc "Cltc公告续航预测值";
CM_ SG_ 656 VCUEstimdCrsRngVld "Estimated range Validty
续航里程有效性";
CM_ SG_ 656 VCUGearChgFailInde "换挡失败提醒";
CM_ SG_ 656 VCUHvBattSysFltIndcr "动力电池故障报警灯 低级";
CM_ SG_ 656 VCUHvBattSysFltWarn "动力电池故障报警灯 严重";
CM_ SG_ 656 VCUHvPwrSysCutOff "VCU发送动力系统切断故障telltale";
CM_ SG_ 656 VCUHVSysFltWarnSts "高压系统故障 分等级";
CM_ SG_ 656 VCUInsEgyCnsDurgDrvg "瞬时电耗 行车状态";
CM_ SG_ 656 VCUInsEgyCnsDurgStsl "瞬时电耗 停车状态";
CM_ SG_ 656 VCUInsEgyCnsFlg "瞬时电耗标志位";
CM_ SG_ 656 VCULoSocWarngMsg "高压电池低电量报警
HV Battery low SOC warnning";
CM_ SG_ 656 VCUPrpsnPwrDrt "VCU发送动力性能降级故障 仪表进行文字显示和声音提醒";
CM_ SG_ 656 VCUThermRunawayErrAlrm "热失控报警";
CM_ SG_ 656 VCUVehSysFltWarn "VCU发送点亮整车系统故障灯信号 仪表点灯";
CM_ SG_ 188 SuspRoadConditionForADD "Road Conditions detected by suspension  transfer to ADD
悬架感知的道路工况";
CM_ SG_ 188 VCUFrntDesTqWoIntv "前轴未干预需求扭矩";
CM_ SG_ 188 VCUFrntDesTqWoIntvVld "前轴未干预需求扭矩有效性";
CM_ SG_ 188 VCUFrntMotActSpd "前电机实际转速";
CM_ SG_ 188 VCUFrntMotActSpdVld "前电机实际转速有效位";
CM_ SG_ 188 VCUFrntMotActTq "前电机实际扭矩 明确为轴端扭矩 非电机端扭矩";
CM_ SG_ 188 VCUFrntMotActTqVld "前电机实际扭矩有效位";
CM_ SG_ 188 VCUFrntMotWhlTqReq "Front motor torque request";
CM_ SG_ 188 VCUFrntMotWhlTqReqVld "Front motor torque request Valid";
CM_ SG_ 188 VCUFrntWhlTqMaxAvl "前轮最大可用扭矩";
CM_ SG_ 188 VCUFrntWhlTqMaxAvlVld "前轮最大可用扭矩有效位";
CM_ SG_ 188 VCUFrntWhlTqMinAvl "前轮最小可用扭矩";
CM_ SG_ 188 VCUFrntWhlTqMinAvlVld "前轮最小可用扭矩有效位";
CM_ SG_ 188 VCUReDesTqWoIntv "后轴未干预需求扭矩";
CM_ SG_ 188 VCUReDesTqWoIntvVld "后轴未干预需求扭矩有效性";
CM_ SG_ 188 VCUReMotActSpd "后电机实际转速";
CM_ SG_ 188 VCUReMotActSpdVld "后电机实际转速有效位";
CM_ SG_ 188 VCUReMotActTq "后电机实际扭矩 明确为轴端扭矩 非电机端扭矩";
CM_ SG_ 188 VCUReMotActTqVld "后电机实际扭矩有效位";
CM_ SG_ 188 VCUReMotWhlTqReq "Rear motor torque request";
CM_ SG_ 188 VCUReMotWhlTqReqVld "Rear motor torque request Valid";
CM_ SG_ 188 VCUReWhlTqMaxAvl "后轮最大可用扭矩";
CM_ SG_ 188 VCUReWhlTqMaxAvlVld "后轮最大可用扭矩有效位";
CM_ SG_ 188 VCUReWhlTqMinAvl "后轮最小可用扭矩";
CM_ SG_ 188 VCUReWhlTqMinAvlVld "后轮最小可用扭矩有效位";
CM_ SG_ 188 VCUWhlTqMaxAvl "Vehicle Total Axle Max ability of Wheel Torque.
整车前后轴总的最大可用扭矩";
CM_ SG_ 188 VCUWhlTqMaxAvlVld "The validation of Vehicle total axle max ability of Wheel Torque.
整车前后轴总的可用回收扭矩的有效位";
CM_ SG_ 188 VDMLgtWhlSpdFL "VDM longitudinal wheel speed front left
左前轮纵向速度";
CM_ SG_ 188 VDMLgtWhlSpdFR "VDM longitudinal wheel speed front right
右前轮纵向速度";
CM_ SG_ 188 VDMLgtWhlSpdRL "VDM longitudinal wheel speed real left
左后轮纵向速度";
CM_ SG_ 188 VDMLgtWhlSpdRR "VDM longitudinal wheel speed rear right
右后轮纵向速度";
CM_ SG_ 188 VehBodySideSlipAng "vehicle body side slip angle";
CM_ SG_ 188 VehLatSpdEstd "lateral vehicle speed estemsted
横向车速";
CM_ SG_ 188 VehLatSpdEstdVld "vehicle lateral speed estimated valid
横向车速有效性";
CM_ SG_ 188 VehLgtSpdEstd "longitudinal vehicle speed estemsted
纵向车速";
CM_ SG_ 188 VehLgtSpdEstdVld "Vehicle longitudinal speed estimated valid
纵向车速有效性";
CM_ SG_ 607 AswmLinComFltSts "ASWM LIN node communication fault status.";
CM_ SG_ 607 HandOnDetnStsSigGrpLinErr "HandOnDetnStsSigGrp LIN communication Error";
CM_ SG_ 607 HandsOnDetectionErrorStatus "方向盘离手检测故障状态";
CM_ SG_ 607 HandsOnDetectionStatus "方向盘离手检测状态";
CM_ SG_ 607 StsOfBSDLampLe "Status Of Left BSD Lamp
左BSD 灯状态";
CM_ SG_ 892 DrvrOcupcySts "Driver Occupancy Sensor Status
主驾座椅占位传感器检测状态";
CM_ SG_ 616 RlsAutWinWipgSpdCmd "雨刮速度请求";
CM_ SG_ 616 RlsFwdLiSnsrVal "前向光线亮度";
CM_ SG_ 616 RlsFwdLiSnsrValUnit "前向光线亮度单位";
CM_ SG_ 616 RlsHudSnsrVal "Hud亮度";
CM_ SG_ 616 RlsHudSnsrValUnit "Hud亮度单位";
CM_ SG_ 616 RlsIRVal "红外光值输出";
CM_ SG_ 616 RlsLiSigGrpLinErr "RlsLiSigGrp LIN communication Error";
CM_ SG_ 616 RlsLiSnsrFwdFlt "RLS光线传感器 前向 故障";
CM_ SG_ 616 RlsLiSnsrIRFlt "RLS光线传感器 IR红外 故障";
CM_ SG_ 616 RlsLiSnsrTopFlt "RLS光线传感器 顶向 故障";
CM_ SG_ 616 RlsOutdBriSts "白天 黑夜 隧道检测";
CM_ SG_ 616 RlsSts "雨量阳光传感器状态";
CM_ SG_ 616 RlsTopLiSnsrVal "Top Light Value
顶向光线亮度";
CM_ SG_ 616 RlsTopLiSnsrValUnit "顶部光线亮度单位";
CM_ SG_ 616 StsOfBSDLampRi "Status Of Right BSD Lamp
右BSD灯状态";
CM_ SG_ 893 PassOcupcySts "Passenger Occupancy Sensor  Status
副驾座椅占位传感器检测状态";
CM_ SG_ 342 ASCFltSts "Air spring control fault status";
CM_ SG_ 342 CDCFltSts "Continuous Daming control fault status";
CM_ SG_ 342 CurDampgCtrlMod "Current active damping control mode";
CM_ SG_ 342 ESPEnaReq "ESC OFF NOT ALLOWED";
CM_ SG_ 342 JackModSts "Level Control deactivation request status  Jack Mode";
CM_ SG_ 342 LvlAdjmtSts "level control mode adjustment status  ie. Lowering from Normal to Low";
CM_ SG_ 342 LvlModAct "Height Level Mode Actual";
CM_ SG_ 342 SCUExtmHeiSts "SCU Extreme Height Status
SCU 悬架极高极低状态";
CM_ SG_ 342 SCULimSpdTqReq "SCU 限速限扭请求
SCU Limit Speed Torque Request";
CM_ SG_ 342 SCUWarnLampReq "SCU Warning Lamp Request
SCU 故障灯请求";
CM_ SG_ 342 SCUWarnMsgASC "SCU Warning Message ASC
空气悬架故障警示信号";
CM_ SG_ 342 SCUWarnMsgCDC "SCU Warning Message CDC
电控减震器故障警示信号";
CM_ SG_ 345 DiagcExtActv "diagnostic external connection activation";
CM_ SG_ 529 SecOCMAC1 "消息认证码1";
CM_ SG_ 529 SecOCMAC2 "消息认证码2";
CM_ SG_ 529 SecOCMAC3 "消息认证码3";
CM_ SG_ 529 SecOCResetCnt "重置计数器";
CM_ SG_ 529 SecOCTripCnt "同步计数器";
CM_ SG_ 549 ADSELKSwtSet "紧急车道保持开关
ADS ELK switch set";
CM_ SG_ 549 ADSFltQuitReqFrmDCD "路面感知系统 SR 监控上游模块失活,请求智驾功能降级";
CM_ SG_ 549 DCDAvmFrCamSts "DCD AVM Front Camera Status";
CM_ SG_ 549 DCDAvmLeCamSts "DCD AVM Left Camera Status";
CM_ SG_ 549 DCDAvmReCamSts "DCD AVM Rear Camera Status";
CM_ SG_ 549 DCDAvmRiCamSts "DCD AVM Rear Camera Status";
CM_ SG_ 549 DCDDisplayFailSts "Center Display Fail Status
座舱中控显示失效状态";
CM_ SG_ 1023 VidBlkId "Block ID for VID Signal sequence";
CM_ SG_ 1023 VidSignalPos1 "1st position in VID Signal - Block ID dependant";
CM_ SG_ 1023 VidSignalPos2 "2st position in VID Signal - Block ID dependant";
CM_ SG_ 1023 VidSignalPos3 "3st position in VID Signal - Block ID dependant";
CM_ SG_ 1023 VidSignalPos4 "4st position in VID Signal - Block ID dependant";
CM_ SG_ 1023 VidSignalPos5 "5st position in VID Signal - Block ID dependant";
CM_ SG_ 1023 VidSignalPos6 "6st position in VID Signal - Block ID dependant";
CM_ SG_ 1023 VidSignalPos7 "7st position in VID Signal - Block ID dependant";
CM_ SG_ 1023 VinVINBlkID "Block ID for VIN Signal sequence";
CM_ SG_ 1023 VinVINSignalPos1 "1st position in VIN Signal    Block ID dependant";
CM_ SG_ 1023 VinVINSignalPos2 "2nd position in VIN Signal   Block ID dependant";
CM_ SG_ 1023 VinVINSignalPos3 "3rd position in VIN Signal   Block ID dependant";
CM_ SG_ 1023 VinVINSignalPos4 "4th position in VIN Signal   Block ID dependant";
CM_ SG_ 1023 VinVINSignalPos5 "5th position in VIN Signal   Block ID dependant";
CM_ SG_ 1023 VinVINSignalPos6 "6th position in VIN Signal   Block ID dependant";
CM_ SG_ 1023 VinVINSignalPos7 "7th position in VIN Signal   Block ID dependant";
CM_ SG_ 135 VehCfgPrmBlkIDBytePosn1 "Block ID for specific Car Configuration parameter sequence";
CM_ SG_ 135 VehCfgPrmCCPBytePosn2 "1st position in specific CCP number sequence   Block ID dependant";
CM_ SG_ 135 VehCfgPrmCCPBytePosn3 "2nd position in specific CCP number sequence   Block ID dependant";
CM_ SG_ 135 VehCfgPrmCCPBytePosn4 "3rd position in specific CCP number sequence   Block ID dependant";
CM_ SG_ 135 VehCfgPrmCCPBytePosn5 "4th position in specific CCP number sequence   Block ID dependant";
CM_ SG_ 135 VehCfgPrmCCPBytePosn6 "5th position in specific CCP number sequence   Block ID dependant";
CM_ SG_ 135 VehCfgPrmCCPBytePosn7 "6th position in specific CCP number sequence   Block ID dependant";
CM_ SG_ 135 VehCfgPrmCCPBytePosn8 "7th position in specific CCP number sequence   Block ID dependant";
CM_ SG_ 389 AdasSwt "一键智驾开关";
CM_ SG_ 389 AdasSwtSigGrpLinErr "AdasSwtSigGrp LIN communication Error";
CM_ SG_ 389 HoodOpenClsSts "Hood Open Close Status
前舱盖开启关闭状态";
CM_ SG_ 389 LeKnobCounter "方向盘左滚轮滚动Counter值";
CM_ SG_ 389 LeKnobRotDir "方向盘左侧滚轮滚动方向
0x0 Idle
0x1 Up
0x2 Down";
CM_ SG_ 389 LeMFctActSgCe "方向盘面板左侧开关滚轮松压状态";
CM_ SG_ 389 LeMFctActSgLe "方向盘面板左侧开关区左侧按键状态";
CM_ SG_ 389 LeMFctActSgRi "方向盘面板左侧开关区右侧按键状态";
CM_ SG_ 389 RiMFctActSgCe "方向盘面板右侧开关滚轮松压状态";
CM_ SG_ 389 TrOpenClsSts "Trunk Open Close Status";
CM_ SG_ 520 ARSPosnSts "Active Rear Spoiler Position Status";
CM_ SG_ 520 HvBattSoCDisp "HV battery State Of Energy for HMI Display / 高压电池剩余可用能量百分比状态信息用于HMI人机交互显示";
CM_ SG_ 520 RlsLinComFltSts "Rls LIN node communication fault status.";
CM_ SG_ 768 FLRLLoPwrSplySts "FLRL Low Power Supply Status
长距激光雷达配电状态";
CM_ SG_ 768 FrntShdADCameraDefrstErrFb "前风挡玻璃局部除雾状态故障反馈";
CM_ SG_ 768 FrntShdADCameraDefrstSts "前风挡智驾摄像头加热状态";
CM_ SG_ 768 IMULoPwrSplySts "IMU Low Power Supply Status
IMU低压配电状态";
CM_ SG_ 768 LockgCenLockSts "中控锁状态";
CM_ SG_ 768 RSRLoPwrSplySts "RSR Low Power Supply Status
后毫米波雷达配电状态";
CM_ SG_ 1313 VCCDChassisBkpActiveWakeup "Active Wakeup Bit";
CM_ SG_ 1313 VCCDChassisBkpNodeAddress "Node source address";
CM_ SG_ 1313 VCCDChassisBkpRepeatMsgReq "Repeat Message Request Bit";
CM_ SG_ 1313 VCCDChassisBkpRepeatMsgSt "Repeat Message State indication";
BA_DEF_ BO_  "CANFD_BRS" ENUM  "0","1";
BA_DEF_ BO_  "GenMsgCycleTime" INT 0 30000;
BA_DEF_ BO_  "GenMsgCycleTimeFast" INT 0 30000;
BA_DEF_ BO_  "GenMsgDelayTime" INT 0 100000;
BA_DEF_ BO_  "GenMsgNrOfRepetition" INT 0 100000;
BA_DEF_ BO_  "GenMsgSendType" ENUM  "cyclic","spontaneous","cyclicIfActive","spontaneousWithDelay","cyclicAndSpontaneous","cyclicAndSpontaneousWithDelay","IfActive","NoMsgSendType";
BA_DEF_ BO_  "GenMsgStartDelayTime" INT 0 100000;
BA_DEF_ BO_  "NmAsrBaseAddress" HEX 0 536870911;
BA_DEF_ BO_  "NmAsrMessage" ENUM  "No","Yes";
BA_DEF_ BO_  "VFrameFormat" ENUM  "StandardCAN","ExtendedCAN","reserved","J1939PG","reserved","reserved","reserved","reserved","reserved","reserved","reserved","reserved","reserved","reserved","StandardCAN_FD","ExtendedCAN_FD";
BA_DEF_ SG_  "GenSigSendType" ENUM  "Cyclic","OnWrite","OnWriteWithRepetition","OnChange","OnChangeWithRepetition","IfActive","IfActiveWithRepetition","NoSigSendType";
BA_DEF_ SG_  "GenSigStartValue" FLOAT -1.79769313486232E+308 1.84467440737096E+019;
BA_DEF_DEF_  "CANFD_BRS" "1";
BA_DEF_DEF_  "GenMsgCycleTime" 0;
BA_DEF_DEF_  "GenMsgCycleTimeFast" 0;
BA_DEF_DEF_  "GenMsgDelayTime" 0;
BA_DEF_DEF_  "GenMsgNrOfRepetition" 0;
BA_DEF_DEF_  "GenMsgSendType" "";
BA_DEF_DEF_  "GenMsgStartDelayTime" 0;
BA_DEF_DEF_  "NmAsrBaseAddress" 1280;
BA_DEF_DEF_  "NmAsrMessage" "No";
BA_DEF_DEF_  "VFrameFormat" "J1939PG";
BA_DEF_DEF_  "GenSigSendType" "Cyclic";
BA_DEF_DEF_  "GenSigStartValue" 0;
BA_ "GenMsgSendType" BO_ 688 0;
BA_ "GenMsgCycleTime" BO_ 688 100;
BA_ "VFrameFormat" BO_ 688 14;
BA_ "GenMsgSendType" BO_ 693 0;
BA_ "GenMsgCycleTime" BO_ 693 100;
BA_ "VFrameFormat" BO_ 693 14;
BA_ "GenMsgSendType" BO_ 775 0;
BA_ "GenMsgCycleTime" BO_ 775 100;
BA_ "VFrameFormat" BO_ 775 14;
BA_ "GenMsgSendType" BO_ 873 4;
BA_ "GenMsgNrOfRepetition" BO_ 873 3;
BA_ "GenMsgCycleTimeFast" BO_ 873 40;
BA_ "GenMsgCycleTime" BO_ 873 1000;
BA_ "VFrameFormat" BO_ 873 14;
BA_ "GenMsgSendType" BO_ 238 1;
BA_ "GenMsgDelayTime" BO_ 238 10;
BA_ "VFrameFormat" BO_ 238 14;
BA_ "GenMsgSendType" BO_ 239 0;
BA_ "GenMsgCycleTime" BO_ 239 10;
BA_ "VFrameFormat" BO_ 239 14;
BA_ "NmAsrMessage" BO_ 1331 1;
BA_ "VFrameFormat" BO_ 1331 0;
BA_ "GenMsgSendType" BO_ 1331 1;
BA_ "GenMsgDelayTime" BO_ 1331 20;
BA_ "NmAsrMessage" BO_ 1326 1;
BA_ "VFrameFormat" BO_ 1326 0;
BA_ "GenMsgSendType" BO_ 1326 1;
BA_ "GenMsgDelayTime" BO_ 1326 20;
BA_ "GenMsgSendType" BO_ 487 0;
BA_ "GenMsgCycleTime" BO_ 487 10;
BA_ "VFrameFormat" BO_ 487 14;
BA_ "GenMsgSendType" BO_ 444 0;
BA_ "GenMsgCycleTime" BO_ 444 20;
BA_ "VFrameFormat" BO_ 444 14;
BA_ "GenMsgSendType" BO_ 657 0;
BA_ "GenMsgCycleTime" BO_ 657 50;
BA_ "VFrameFormat" BO_ 657 14;
BA_ "GenMsgSendType" BO_ 663 1;
BA_ "GenMsgDelayTime" BO_ 663 5;
BA_ "VFrameFormat" BO_ 663 14;
BA_ "GenMsgSendType" BO_ 665 0;
BA_ "GenMsgCycleTime" BO_ 665 50;
BA_ "VFrameFormat" BO_ 665 14;
BA_ "GenMsgSendType" BO_ 758 0;
BA_ "GenMsgCycleTime" BO_ 758 100;
BA_ "VFrameFormat" BO_ 758 14;
BA_ "GenMsgSendType" BO_ 817 0;
BA_ "GenMsgCycleTime" BO_ 817 50;
BA_ "VFrameFormat" BO_ 817 14;
BA_ "GenMsgSendType" BO_ 825 1;
BA_ "GenMsgDelayTime" BO_ 825 5;
BA_ "VFrameFormat" BO_ 825 14;
BA_ "GenMsgSendType" BO_ 826 0;
BA_ "GenMsgCycleTime" BO_ 826 50;
BA_ "VFrameFormat" BO_ 826 14;
BA_ "GenMsgSendType" BO_ 827 1;
BA_ "GenMsgDelayTime" BO_ 827 5;
BA_ "VFrameFormat" BO_ 827 14;
BA_ "GenMsgSendType" BO_ 581 0;
BA_ "GenMsgCycleTime" BO_ 581 50;
BA_ "VFrameFormat" BO_ 581 14;
BA_ "GenMsgSendType" BO_ 355 0;
BA_ "GenMsgCycleTime" BO_ 355 20;
BA_ "VFrameFormat" BO_ 355 14;
BA_ "GenMsgSendType" BO_ 994 0;
BA_ "GenMsgCycleTime" BO_ 994 1000;
BA_ "VFrameFormat" BO_ 994 14;
BA_ "GenMsgSendType" BO_ 200 0;
BA_ "GenMsgCycleTime" BO_ 200 10;
BA_ "VFrameFormat" BO_ 200 14;
BA_ "GenMsgSendType" BO_ 515 0;
BA_ "GenMsgCycleTime" BO_ 515 50;
BA_ "VFrameFormat" BO_ 515 14;
BA_ "GenMsgSendType" BO_ 656 0;
BA_ "GenMsgCycleTime" BO_ 656 100;
BA_ "VFrameFormat" BO_ 656 14;
BA_ "GenMsgSendType" BO_ 188 0;
BA_ "GenMsgCycleTime" BO_ 188 10;
BA_ "VFrameFormat" BO_ 188 14;
BA_ "GenMsgSendType" BO_ 607 0;
BA_ "GenMsgCycleTime" BO_ 607 50;
BA_ "VFrameFormat" BO_ 607 14;
BA_ "GenMsgSendType" BO_ 892 0;
BA_ "GenMsgCycleTime" BO_ 892 200;
BA_ "VFrameFormat" BO_ 892 14;
BA_ "GenMsgSendType" BO_ 616 0;
BA_ "GenMsgCycleTime" BO_ 616 50;
BA_ "VFrameFormat" BO_ 616 14;
BA_ "GenMsgSendType" BO_ 893 0;
BA_ "GenMsgCycleTime" BO_ 893 200;
BA_ "VFrameFormat" BO_ 893 14;
BA_ "GenMsgSendType" BO_ 342 0;
BA_ "GenMsgCycleTime" BO_ 342 20;
BA_ "VFrameFormat" BO_ 342 14;
BA_ "GenMsgSendType" BO_ 345 0;
BA_ "GenMsgCycleTime" BO_ 345 20;
BA_ "VFrameFormat" BO_ 345 14;
BA_ "GenMsgSendType" BO_ 529 1;
BA_ "GenMsgDelayTime" BO_ 529 2;
BA_ "VFrameFormat" BO_ 529 14;
BA_ "GenMsgSendType" BO_ 549 0;
BA_ "GenMsgCycleTime" BO_ 549 50;
BA_ "VFrameFormat" BO_ 549 14;
BA_ "GenMsgSendType" BO_ 1023 0;
BA_ "GenMsgCycleTime" BO_ 1023 1000;
BA_ "VFrameFormat" BO_ 1023 14;
BA_ "GenMsgSendType" BO_ 135 1;
BA_ "GenMsgDelayTime" BO_ 135 10;
BA_ "VFrameFormat" BO_ 135 14;
BA_ "GenMsgSendType" BO_ 389 0;
BA_ "GenMsgCycleTime" BO_ 389 20;
BA_ "VFrameFormat" BO_ 389 14;
BA_ "GenMsgSendType" BO_ 520 0;
BA_ "GenMsgCycleTime" BO_ 520 50;
BA_ "VFrameFormat" BO_ 520 14;
BA_ "GenMsgSendType" BO_ 768 0;
BA_ "GenMsgCycleTime" BO_ 768 100;
BA_ "VFrameFormat" BO_ 768 14;
BA_ "NmAsrMessage" BO_ 1313 1;
BA_ "VFrameFormat" BO_ 1313 0;
BA_ "GenMsgSendType" BO_ 1313 1;
BA_ "GenMsgDelayTime" BO_ 1313 20;
BA_ "GenSigStartValue" SG_ 775 ParkProgressSigLFPosXFrmADD 65535;
BA_ "GenSigStartValue" SG_ 775 ParkProgressSigLFPosYFrmADD 65535;
BA_ "GenSigStartValue" SG_ 775 ParkProgressSigLRPosXFrmADD 65535;
BA_ "GenSigStartValue" SG_ 775 ParkProgressSigLRPosYFrmADD 65535;
BA_ "GenSigStartValue" SG_ 775 ParkProgressSigRFPosXFrmADD 65535;
BA_ "GenSigStartValue" SG_ 775 ParkProgressSigRFPosYFrmADD 65535;
BA_ "GenSigStartValue" SG_ 775 ParkProgressSigRRPosXFrmADD 65535;
BA_ "GenSigStartValue" SG_ 775 ParkProgressSigRRPosYFrmADD 65535;
BA_ "GenSigSendType" SG_ 873 LowPwrReqFrLdrFrmADD 1;
BA_ "GenSigSendType" SG_ 873 LowPwrReqFrRdrFrmADD 1;
BA_ "GenSigSendType" SG_ 238 ADD2BLEMForRPA00 1;
BA_ "GenSigSendType" SG_ 238 ADD2BLEMForRPA00FV 1;
BA_ "GenSigSendType" SG_ 238 ADD2BLEMForRPA00MAC 1;
BA_ "GenSigSendType" SG_ 238 ADD2BLEMForRPA01 1;
BA_ "GenSigSendType" SG_ 238 ADD2BLEMForRPA02 1;
BA_ "GenSigSendType" SG_ 238 ADD2BLEMForRPA03 1;
BA_ "GenSigSendType" SG_ 1331 ADDChassisBkpActiveWakeup 1;
BA_ "GenSigSendType" SG_ 1331 ADDChassisBkpNodeAddress 1;
BA_ "GenSigSendType" SG_ 1331 ADDChassisBkpRepeatMsgReq 1;
BA_ "GenSigSendType" SG_ 1331 ADDChassisBkpRepeatMsgSt 1;
BA_ "GenSigSendType" SG_ 1331 NMKeepAwkRsnADD 1;
BA_ "GenSigSendType" SG_ 1331 UDB17ADD 1;
BA_ "GenSigSendType" SG_ 1331 UDB18ADD 1;
BA_ "GenSigSendType" SG_ 1331 UDB19ADD 1;
BA_ "GenSigSendType" SG_ 1331 UDB20ADD 1;
BA_ "GenSigSendType" SG_ 1331 UDB21ADD 1;
BA_ "GenSigSendType" SG_ 1331 UDB22ADD 1;
BA_ "GenSigSendType" SG_ 1331 UDB23ADD 1;
BA_ "GenSigSendType" SG_ 1331 UDB24ADD 1;
BA_ "GenSigSendType" SG_ 1331 UDB25ADD 1;
BA_ "GenSigSendType" SG_ 1331 UDB26ADD 1;
BA_ "GenSigSendType" SG_ 1331 UDB27ADD 1;
BA_ "GenSigSendType" SG_ 1331 UDB28ADD 1;
BA_ "GenSigSendType" SG_ 1331 UDB29ADD 1;
BA_ "GenSigSendType" SG_ 1331 UDB30ADD 1;
BA_ "GenSigSendType" SG_ 1331 UDB31ADD 1;
BA_ "GenSigSendType" SG_ 1331 UDB32ADD 1;
BA_ "GenSigSendType" SG_ 1331 UDB33ADD 1;
BA_ "GenSigSendType" SG_ 1331 UDB34ADD 1;
BA_ "GenSigSendType" SG_ 1331 UDB35ADD 1;
BA_ "GenSigSendType" SG_ 1331 UDB36ADD 1;
BA_ "GenSigSendType" SG_ 1331 UDB37ADD 1;
BA_ "GenSigSendType" SG_ 1331 UDB38ADD 1;
BA_ "GenSigSendType" SG_ 1331 UDB39ADD 1;
BA_ "GenSigSendType" SG_ 1331 UDB40ADD 1;
BA_ "GenSigSendType" SG_ 1331 UDB41ADD 1;
BA_ "GenSigSendType" SG_ 1331 UDB42ADD 1;
BA_ "GenSigSendType" SG_ 1331 UDB43ADD 1;
BA_ "GenSigSendType" SG_ 1331 UDB44ADD 1;
BA_ "GenSigSendType" SG_ 1331 UDB45ADD 1;
BA_ "GenSigSendType" SG_ 1331 UDB46ADD 1;
BA_ "GenSigSendType" SG_ 1331 UDB47ADD 1;
BA_ "GenSigSendType" SG_ 1326 ADDChassisBkpActiveWakeup1 1;
BA_ "GenSigSendType" SG_ 1326 ADDChassisBkpNodeAddress1 1;
BA_ "GenSigSendType" SG_ 1326 ADDChassisBkpRepeatMsgReq1 1;
BA_ "GenSigSendType" SG_ 1326 ADDChassisBkpRepeatMsgSt1 1;
BA_ "GenSigSendType" SG_ 1326 NMKeepAwkRsnADD 1;
BA_ "GenSigSendType" SG_ 1326 UDB17ADD 1;
BA_ "GenSigSendType" SG_ 1326 UDB18ADD 1;
BA_ "GenSigSendType" SG_ 1326 UDB19ADD 1;
BA_ "GenSigSendType" SG_ 1326 UDB20ADD 1;
BA_ "GenSigSendType" SG_ 1326 UDB21ADD 1;
BA_ "GenSigSendType" SG_ 1326 UDB22ADD 1;
BA_ "GenSigSendType" SG_ 1326 UDB23ADD 1;
BA_ "GenSigSendType" SG_ 1326 UDB24ADD 1;
BA_ "GenSigSendType" SG_ 1326 UDB25ADD 1;
BA_ "GenSigSendType" SG_ 1326 UDB26ADD 1;
BA_ "GenSigSendType" SG_ 1326 UDB27ADD 1;
BA_ "GenSigSendType" SG_ 1326 UDB28ADD 1;
BA_ "GenSigSendType" SG_ 1326 UDB29ADD 1;
BA_ "GenSigSendType" SG_ 1326 UDB30ADD 1;
BA_ "GenSigSendType" SG_ 1326 UDB31ADD 1;
BA_ "GenSigSendType" SG_ 1326 UDB32ADD 1;
BA_ "GenSigSendType" SG_ 1326 UDB33ADD 1;
BA_ "GenSigSendType" SG_ 1326 UDB34ADD 1;
BA_ "GenSigSendType" SG_ 1326 UDB35ADD 1;
BA_ "GenSigSendType" SG_ 1326 UDB36ADD 1;
BA_ "GenSigSendType" SG_ 1326 UDB37ADD 1;
BA_ "GenSigSendType" SG_ 1326 UDB38ADD 1;
BA_ "GenSigSendType" SG_ 1326 UDB39ADD 1;
BA_ "GenSigSendType" SG_ 1326 UDB40ADD 1;
BA_ "GenSigSendType" SG_ 1326 UDB41ADD 1;
BA_ "GenSigSendType" SG_ 1326 UDB42ADD 1;
BA_ "GenSigSendType" SG_ 1326 UDB43ADD 1;
BA_ "GenSigSendType" SG_ 1326 UDB44ADD 1;
BA_ "GenSigSendType" SG_ 1326 UDB45ADD 1;
BA_ "GenSigSendType" SG_ 1326 UDB46ADD 1;
BA_ "GenSigSendType" SG_ 1326 UDB47ADD 1;
BA_ "GenSigStartValue" SG_ 487 BrkSysFTarDrvr 2047;
BA_ "GenSigSendType" SG_ 663 DltAllKeyFbFV 1;
BA_ "GenSigSendType" SG_ 663 DltAllKeyFbMAC 1;
BA_ "GenSigSendType" SG_ 663 SndBLEKeyPosnToRPA 1;
BA_ "GenSigStartValue" SG_ 758 FrntLeTyrePVal 254;
BA_ "GenSigStartValue" SG_ 758 FrntRiTyrePVal 254;
BA_ "GenSigStartValue" SG_ 758 ReLeTyrePVal 254;
BA_ "GenSigStartValue" SG_ 758 ReRiTyrePVal 254;
BA_ "GenSigSendType" SG_ 825 BLEM2ADDForRPA00 1;
BA_ "GenSigSendType" SG_ 825 BLEM2ADDForRPA00FV 1;
BA_ "GenSigSendType" SG_ 825 BLEM2ADDForRPA00MAC 1;
BA_ "GenSigSendType" SG_ 825 BLEM2ADDForRPA01 1;
BA_ "GenSigSendType" SG_ 825 BLEM2ADDForRPA02 1;
BA_ "GenSigSendType" SG_ 825 BLEM2ADDForRPA03 1;
BA_ "GenSigSendType" SG_ 827 BLEM2VCCDForRkeReq00 1;
BA_ "GenSigSendType" SG_ 827 BLEM2VCCDForRkeReq01 1;
BA_ "GenSigSendType" SG_ 827 BLEM2VCCDForRkeReq02 1;
BA_ "GenSigSendType" SG_ 827 BLEM2VCCDForRkeReq03 1;
BA_ "GenSigSendType" SG_ 827 BLEM2VCCDForRkeReq04 1;
BA_ "GenSigSendType" SG_ 827 BLEM2VCCDForRkeReq05 1;
BA_ "GenSigSendType" SG_ 827 BLEM2VCCDForRkeReq06 1;
BA_ "GenSigSendType" SG_ 827 BLEM2VCCDForRkeReq07 1;
BA_ "GenSigSendType" SG_ 827 BLEM2VCCDForRkeReq08 1;
BA_ "GenSigSendType" SG_ 827 BLEM2VCCDForRkeReq09 1;
BA_ "GenSigSendType" SG_ 827 BLEM2VCCDForRkeReq10 1;
BA_ "GenSigSendType" SG_ 827 BLEM2VCCDForRkeReq11 1;
BA_ "GenSigSendType" SG_ 827 BLEM2VCCDForRkeReq12 1;
BA_ "GenSigSendType" SG_ 827 BLEM2VCCDForRkeReq13 1;
BA_ "GenSigSendType" SG_ 827 BLEM2VCCDForRkeReq14 1;
BA_ "GenSigSendType" SG_ 827 BLEM2VCCDForRkeReqFV 1;
BA_ "GenSigSendType" SG_ 827 BLEM2VCCDForRkeReqMAC 1;
BA_ "GenSigStartValue" SG_ 581 BattSoh 900;
BA_ "GenSigStartValue" SG_ 994 CwEOTValueBkp 12480;
BA_ "GenSigStartValue" SG_ 656 VCUEgyCnsInCurDrvCyc 20000;
BA_ "GenSigStartValue" SG_ 188 VCUFrntDesTqWoIntv 16383;
BA_ "GenSigStartValue" SG_ 188 VCUFrntMotActSpd 32767;
BA_ "GenSigStartValue" SG_ 188 VCUFrntMotActTq 16383;
BA_ "GenSigStartValue" SG_ 188 VCUFrntMotWhlTqReq 16383;
BA_ "GenSigStartValue" SG_ 188 VCUFrntWhlTqMinAvl 16383;
BA_ "GenSigStartValue" SG_ 188 VCUReDesTqWoIntv 16383;
BA_ "GenSigStartValue" SG_ 188 VCUReMotActSpd 32767;
BA_ "GenSigStartValue" SG_ 188 VCUReMotActTq 16383;
BA_ "GenSigStartValue" SG_ 188 VCUReMotWhlTqReq 16383;
BA_ "GenSigStartValue" SG_ 188 VCUReWhlTqMinAvl 16383;
BA_ "GenSigStartValue" SG_ 342 CurDampgCtrlMod 1;
BA_ "GenSigStartValue" SG_ 342 LvlModAct 3;
BA_ "GenSigSendType" SG_ 529 SecOCMAC1 1;
BA_ "GenSigSendType" SG_ 529 SecOCMAC2 1;
BA_ "GenSigSendType" SG_ 529 SecOCMAC3 1;
BA_ "GenSigSendType" SG_ 529 SecOCResetCnt 1;
BA_ "GenSigSendType" SG_ 529 SecOCTripCnt 1;
BA_ "GenSigStartValue" SG_ 1023 VidBlkId 1;
BA_ "GenSigStartValue" SG_ 1023 VinVINBlkID 1;
BA_ "GenSigStartValue" SG_ 135 VehCfgPrmBlkIDBytePosn1 1;
BA_ "GenSigSendType" SG_ 135 VehCfgPrmBlkIDBytePosn1 1;
BA_ "GenSigSendType" SG_ 135 VehCfgPrmCCPBytePosn2 1;
BA_ "GenSigSendType" SG_ 135 VehCfgPrmCCPBytePosn3 1;
BA_ "GenSigSendType" SG_ 135 VehCfgPrmCCPBytePosn4 1;
BA_ "GenSigSendType" SG_ 135 VehCfgPrmCCPBytePosn5 1;
BA_ "GenSigSendType" SG_ 135 VehCfgPrmCCPBytePosn6 1;
BA_ "GenSigSendType" SG_ 135 VehCfgPrmCCPBytePosn7 1;
BA_ "GenSigSendType" SG_ 135 VehCfgPrmCCPBytePosn8 1;
BA_ "GenSigSendType" SG_ 1313 NMKeepAwkRsnVCCD 1;
BA_ "GenSigSendType" SG_ 1313 UDB17VCCD 1;
BA_ "GenSigSendType" SG_ 1313 UDB18VCCD 1;
BA_ "GenSigSendType" SG_ 1313 UDB19VCCD 1;
BA_ "GenSigSendType" SG_ 1313 UDB20VCCD 1;
BA_ "GenSigSendType" SG_ 1313 UDB21VCCD 1;
BA_ "GenSigSendType" SG_ 1313 UDB22VCCD 1;
BA_ "GenSigSendType" SG_ 1313 UDB23VCCD 1;
BA_ "GenSigSendType" SG_ 1313 UDB24VCCD 1;
BA_ "GenSigSendType" SG_ 1313 UDB25VCCD 1;
BA_ "GenSigSendType" SG_ 1313 UDB26VCCD 1;
BA_ "GenSigSendType" SG_ 1313 UDB27VCCD 1;
BA_ "GenSigSendType" SG_ 1313 UDB28VCCD 1;
BA_ "GenSigSendType" SG_ 1313 UDB29VCCD 1;
BA_ "GenSigSendType" SG_ 1313 UDB30VCCD 1;
BA_ "GenSigSendType" SG_ 1313 UDB31VCCD 1;
BA_ "GenSigSendType" SG_ 1313 UDB32VCCD 1;
BA_ "GenSigSendType" SG_ 1313 UDB33VCCD 1;
BA_ "GenSigSendType" SG_ 1313 UDB34VCCD 1;
BA_ "GenSigSendType" SG_ 1313 UDB35VCCD 1;
BA_ "GenSigSendType" SG_ 1313 UDB36VCCD 1;
BA_ "GenSigSendType" SG_ 1313 UDB37VCCD 1;
BA_ "GenSigSendType" SG_ 1313 UDB38VCCD 1;
BA_ "GenSigSendType" SG_ 1313 UDB39VCCD 1;
BA_ "GenSigSendType" SG_ 1313 UDB40VCCD 1;
BA_ "GenSigSendType" SG_ 1313 UDB41VCCD 1;
BA_ "GenSigSendType" SG_ 1313 UDB42VCCD 1;
BA_ "GenSigSendType" SG_ 1313 UDB43VCCD 1;
BA_ "GenSigSendType" SG_ 1313 UDB44VCCD 1;
BA_ "GenSigSendType" SG_ 1313 UDB45VCCD 1;
BA_ "GenSigSendType" SG_ 1313 UDB46VCCD 1;
BA_ "GenSigSendType" SG_ 1313 UDB47VCCD 1;
BA_ "GenSigSendType" SG_ 1313 UDB49VCCD 1;
BA_ "GenSigSendType" SG_ 1313 UDB50VCCD 1;
BA_ "GenSigSendType" SG_ 1313 UDB51VCCD 1;
BA_ "GenSigSendType" SG_ 1313 UDB52VCCD 1;
BA_ "GenSigSendType" SG_ 1313 UDB53VCCD 1;
BA_ "GenSigSendType" SG_ 1313 VCCDChassisBkpActiveWakeup 1;
BA_ "GenSigSendType" SG_ 1313 VCCDChassisBkpNodeAddress 1;
BA_ "GenSigSendType" SG_ 1313 VCCDChassisBkpRepeatMsgReq 1;
BA_ "GenSigSendType" SG_ 1313 VCCDChassisBkpRepeatMsgSt 1;
VAL_ 688 ADDFaultInfoFlag 0 "No_Fault" 1 "Fault" ;
VAL_ 688 ADSLrnUnavlRsnFrmADD 0 "default" 1 "No_reason_req" 2 "account_not_log_in" 3 "not_P_gear" 4 "not_authorized" ;
VAL_ 688 ADSParkSpdSwtStsFrmADD 0 "default" 1 "Standard" 2 "Fast" 3 "Unavailable" 4 "Reserved_1" 5 "Reserved_2" 6 "Reserved_3" 7 "Reserved_4" ;
VAL_ 688 ADSParkSpdSwtUnavlRsnFrmADD 0 "default" 1 "No_reason_req" 2 "not_P_gear" 3 "account_not_log_in" 4 "not_authorized" 5 "not_learned" 6 "privacy_mode" 7 "extreme_eco_mode" 8 "lowpower_mode" 9 "function_active" 10 "other_reasons" 11 "Error_detected" ;
VAL_ 688 APASwtStsFrmADD 0 "default" 1 "Off" 2 "ON" 3 "unavailable" 4 "On_not_support_click" 5 "ON&Active" 6 "Off_not_support_click" ;
VAL_ 688 APASwtUnavlRsnFrmADD 0 "default" 1 "No_reason_req" 2 "not_P_gear" 3 "account_not_log_in" 4 "not_authorized" 5 "not_learned" 6 "privacy_mode" 7 "extreme_eco_mode" 8 "lowpower_mode" 9 "function_active" 10 "other_reasons" 11 "Error_detected" ;
VAL_ 688 AutoVehCustEIPSwtFrmADD 0 "defualt" 1 "Off" 2 "On" 3 "Off_no_click" 4 "On_no_click" ;
VAL_ 688 AutoVehCustEIPSwtRsnFrmADD 0 "default" 1 "No_reason_req" 2 "not_P_gear" 3 "account_not_log_in" ;
VAL_ 688 AutoVehSrvAuthntStsFrmADD 0 "default" 1 "unauthorized" 2 "authorized" 3 "unauthorized_no_click" 4 "authorized_no_click" ;
VAL_ 688 AutoVehSrvAuthntStsRsnFrmADD 0 "default" 1 "No_reason_req" 2 "not_P_gear" 3 "account_not_log_in" ;
VAL_ 688 AvmCamTriggerModReqFrmADD 0 "NoReq" 1 "XcdControlRequest" 2 "AddControlRequest" 3 "Reserved" ;
VAL_ 688 AVPSwtStsFrmADD 0 "default" 1 "Off" 2 "ON" 3 "unavailable" 4 "On_not_support_click" 5 "ON_Active" 6 "Off_not_support_click" 7 "Reserved" ;
VAL_ 688 AVPSwtUnavlRsnFrmADD 0 "default" 1 "No_reason_req" 2 "not_P_gear" 3 "account_not_log_in" 4 "not_authorized" 5 "not_learned" 6 "privacy_mode" 7 "extreme_eco_mode" 8 "lowpower_mode" 9 "function_active" 10 "adas_not_purchased" 11 "Error_detected" 12 "location_limited" 13 "Reserved" 14 "Reserved" 15 "Reserved" ;
VAL_ 688 HPPBckGrLearFrmADD 0 "default" 1 "Off" 2 "ON" 3 "unavailable" 4 "On_not_support_click" 5 "ON_Active" 6 "Off_not_support_click" 7 "Reserved" ;
VAL_ 688 HPPBckGrLearUnavlRsnFrmADD 0 "default" 1 "No_reason_req" 2 "not_P_gear" 3 "account_not_log_in" 4 "not_authorized" 5 "not_learned" 6 "privacy_mode" 7 "extreme_eco_mode" 8 "lowpower_mode" 9 "function_active" 10 "other_reasons" 11 "Error_detected" 12 "location_limited" 13 "Reserved" 14 "Reserved" 15 "Reserved" ;
VAL_ 688 HPPSwtStsFrmADD 0 "default" 1 "Off" 2 "ON" 3 "unavailable" 4 "On_not_support_click" 5 "ON_Active" 6 "Off_not_support_click" 7 "Reserved" ;
VAL_ 688 HPPSwtUnavlRsnFrmADD 0 "default" 1 "No_reason_req" 2 "not_P_gear" 3 "account_not_log_in" 4 "not_authorized" 5 "not_learned" 6 "privacy_mode" 7 "extreme_eco_mode" 8 "lowpower_mode" 9 "function_active" 10 "adas_not_purchased" 11 "Error_detected" 12 "location_limited" 13 "Reserved" 14 "Reserved" 15 "Reserved" ;
VAL_ 688 RPASentryQuit 0 "No_Req" 1 "RPA_Sentry_Quit_Req" ;
VAL_ 693 ParkOutTarDirFrmADD 0 "None" 1 "Left" 2 "Right" ;
VAL_ 693 ParkSlotTarFrmADD 0 "None" 1 "L1" 2 "L2" 3 "L3" 4 "L4" 5 "L5" 6 "L6" 7 "L7" 8 "L8" 9 "R1" 10 "R2" 11 "R3" 12 "R4" 13 "R5" 14 "R6" 15 "R7" 16 "R8" ;
VAL_ 693 PASBuzzerWarnMuteReqFrmADD 0 "No_Request" 1 "Request" ;
VAL_ 693 PASFCBuzzerWarnFrmADD 0 "No_object" 1 "Level1" 2 "Level2" 3 "Level3" 4 "Level4" 5 "Level5" ;
VAL_ 693 PASFLBuzzerWarnFrmADD 0 "No_object" 1 "Level1" 2 "Level2" 3 "Level3" 4 "Level4" 5 "Level5" ;
VAL_ 693 PASFLDistanceLevFrmADD 0 "No_object" 1 "Level1" 2 "Level2" 3 "Level3" 4 "Level4" 5 "Level5" 6 "Level6" ;
VAL_ 693 PASFMLDistanceLevFrmADD 0 "No_object" 1 "Level1" 2 "Level2" 3 "Level3" 4 "Level4" 5 "Level5" 6 "Level6" ;
VAL_ 693 PASFMRDistanceLevFrmADD 0 "No_object" 1 "Level1" 2 "Level2" 3 "Level3" 4 "Level4" 5 "Level5" 6 "Level6" ;
VAL_ 693 PASFRBuzzerWarnFrmADD 0 "No_object" 1 "Level1" 2 "Level2" 3 "Level3" 4 "Level4" 5 "Level5" ;
VAL_ 693 PASFRDistanceLevFrmADD 0 "No_object" 1 "Level1" 2 "Level2" 3 "Level3" 4 "Level4" 5 "Level5" 6 "Level6" ;
VAL_ 693 PASFSLDistanceLevFrmADD 0 "No_object" 1 "Level1" 2 "Level2" 3 "Level3" 4 "Level4" 5 "Level5" 6 "Level6" ;
VAL_ 693 PASFSRDistanceLevFrmADD 0 "No_object" 1 "Level1" 2 "Level2" 3 "Level3" 4 "Level4" 5 "Level5" 6 "Level6" ;
VAL_ 693 PASRLBuzzerWarnFrmADD 0 "No_object" 1 "Level1" 2 "Level2" 3 "Level3" 4 "Level4" 5 "Level5" ;
VAL_ 693 PASRLDistanceLevFrmADD 0 "No_object" 1 "Level1" 2 "Level2" 3 "Level3" 4 "Level4" 5 "Level5" 6 "Level6" ;
VAL_ 693 PASRMLDistanceLevFrmADD 0 "No_object" 1 "Level1" 2 "Level2" 3 "Level3" 4 "Level4" 5 "Level5" 6 "Level6" ;
VAL_ 693 PASRMRDistanceLevFrmADD 0 "No_object" 1 "Level1" 2 "Level2" 3 "Level3" 4 "Level4" 5 "Level5" 6 "Level6" ;
VAL_ 693 PASRRBuzzerWarnFrmADD 0 "No_object" 1 "Level1" 2 "Level2" 3 "Level3" 4 "Level4" 5 "Level5" ;
VAL_ 693 PASRRDistanceLevFrmADD 0 "No_object" 1 "Level1" 2 "Level2" 3 "Level3" 4 "Level4" 5 "Level5" 6 "Level6" ;
VAL_ 693 PASRSLDistanceLevFrmADD 0 "No_object" 1 "Level1" 2 "Level2" 3 "Level3" 4 "Level4" 5 "Level5" 6 "Level6" ;
VAL_ 693 PASRSRDistanceLevFrmADD 0 "No_object" 1 "Level1" 2 "Level2" 3 "Level3" 4 "Level4" 5 "Level5" 6 "Level6" ;
VAL_ 693 PASSDWFLSideDistanceLevFrmADD 0 "No_object" 1 "Level1" 2 "Level2" 3 "Level3" 4 "Level4" 5 "Level5" 6 "Level6" ;
VAL_ 693 PASSDWFMLSideDistanceLevFrmADD 0 "No_object" 1 "Level1" 2 "Level2" 3 "Level3" 4 "Level4" 5 "Level5" 6 "Level6" ;
VAL_ 693 PASSDWFMRSideDistanceLevFrmADD 0 "No_object" 1 "Level1" 2 "Level2" 3 "Level3" 4 "Level4" 5 "Level5" 6 "Level6" ;
VAL_ 693 PASSDWFRSideDistanceLevFrmADD 0 "No_object" 1 "Level1" 2 "Level2" 3 "Level3" 4 "Level4" 5 "Level5" 6 "Level6" ;
VAL_ 693 PASSDWRLSideDistanceLevFrmADD 0 "No_object" 1 "Level1" 2 "Level2" 3 "Level3" 4 "Level4" 5 "Level5" 6 "Level6" ;
VAL_ 693 PASSDWRMLSideDistanceLevFrmADD 0 "No_object" 1 "Level1" 2 "Level2" 3 "Level3" 4 "Level4" 5 "Level5" 6 "Level6" ;
VAL_ 693 PASSDWRMRSideDistanceLevFrmADD 0 "No_object" 1 "Level1" 2 "Level2" 3 "Level3" 4 "Level4" 5 "Level5" 6 "Level6" ;
VAL_ 693 PASSDWRRSideDistanceLevFrmADD 0 "No_object" 1 "Level1" 2 "Level2" 3 "Level3" 4 "Level4" 5 "Level5" 6 "Level6" ;
VAL_ 775 ParkProgressSigLFPosXFrmADD 65535 "Invalid" ;
VAL_ 775 ParkProgressSigLFPosYFrmADD 65535 "Invalid" ;
VAL_ 775 ParkProgressSigLRPosXFrmADD 65535 "Invalid" ;
VAL_ 775 ParkProgressSigLRPosYFrmADD 65535 "Invalid" ;
VAL_ 775 ParkProgressSigRFPosXFrmADD 65535 "Invalid" ;
VAL_ 775 ParkProgressSigRFPosYFrmADD 65535 "Invalid" ;
VAL_ 775 ParkProgressSigRRPosXFrmADD 65535 "Invalid" ;
VAL_ 775 ParkProgressSigRRPosYFrmADD 65535 "Invalid" ;
VAL_ 775 PASSubFunAvaiFrmADD 0 "Available" 1 "Front_Not_Available_Rear_Available" 2 "Rear_Not_Available_Front__Available" 3 "Only_SDW_Not_Available" 4 "Not_Available" 5 "PAS_Initialization" 6 "Lowpower_Mode" 7 "Other_Reasons" ;
VAL_ 775 PASWorkingModeFrmADD 0 "Off" 1 "Standby" 2 "Active" 3 "SystemFailure" ;
VAL_ 873 LowPwrReqFrLdrFrmADD 0 "default" 1 "exit_request" 2 "enter_requet" ;
VAL_ 873 LowPwrReqFrRdrFrmADD 0 "default" 1 "exit_request" 2 "enter_requet" ;
VAL_ 239 XAccelStaFrmADD 0 "available" 1 "abnormal" 2 "outrange" 3 "CRC_check_failed" ;
VAL_ 239 XAngRateStaFrmADD 0 "available" 1 "abnormal" 2 "outrange" 3 "CRC_check_failed" ;
VAL_ 239 YAccelStaFrmADD 0 "available" 1 "abnormal" 2 "outrange" 3 "CRC_check_failed" ;
VAL_ 239 YAngRateStaFrmADD 0 "available" 1 "abnormal" 2 "outrange" 3 "CRC_check_failed" ;
VAL_ 239 ZAccelStaFrmADD 0 "available" 1 "abnormal" 2 "outrange" 3 "CRC_check_failed" ;
VAL_ 239 ZAngRateStaFrmADD 0 "available" 1 "abnormal" 2 "outrange" 3 "CRC_check_failed" ;
VAL_ 1331 ADDChassisBkpActiveWakeup 0 "passive_wakeup" 1 "active_Wakeup" ;
VAL_ 1331 ADDChassisBkpRepeatMsgReq 0 "Repeat_Message_State_not_requested" 1 "Repeat_Message_State_requested" ;
VAL_ 1331 ADDChassisBkpRepeatMsgSt 0 "Not_in_Repeat_Message_State" 1 "In_Repeat_Message_State" ;
VAL_ 1326 ADDChassisBkpActiveWakeup1 0 "passive_wakeup" 1 "active_Wakeup" ;
VAL_ 1326 ADDChassisBkpRepeatMsgReq1 0 "Repeat_Message_State_not_requested" 1 "Repeat_Message_State_requested" ;
VAL_ 1326 ADDChassisBkpRepeatMsgSt1 0 "Not_in_Repeat_Message_State" 1 "In_Repeat_Message_State" ;
VAL_ 487 BrkSysBrkPedlAppld 0 "NotApplied" 1 "Applied" ;
VAL_ 487 BrkSysBrkPedlAppldVld 0 "BrkPedlAppld_NotInitialized" 1 "BrkPedlAppld_Normal" 2 "BrkPedlAppld_Faulty" ;
VAL_ 487 BrkSysEnaActvCtrlByDrvr 0 "NotEnable" 1 "Enable" ;
VAL_ 487 BrkSysFTarDrvrVld 0 "NotInitialized" 1 "Normal" 2 "ExternalBrakeRequest" 3 "Faulty" ;
VAL_ 487 BrkSysPRednPotnlVld 0 "NotInitialized" 1 "Normal" 2 "Faulty" ;
VAL_ 487 BrkSysWarnLampReq 0 "NoLamp" 1 "YellowLamp" 2 "RedLamp" ;
VAL_ 444 RCAvailable 0 "Not_Available" 1 "Available" ;
VAL_ 444 RPARemReq 0 "No_Request" 1 "RPA_Request" 2 "Reserved1" 3 "Reserved1" ;
VAL_ 663 SndBLEKeyPosnToRPA 0 "Initial_value" 1 "R0_distance" 2 "R1_distance" 3 "R2_distance" 4 "R3_distance" 5 "R4_distance" ;
VAL_ 758 FrntLeTyrePVal 255 "Invalid" ;
VAL_ 758 FrntLeTyrePWarn 0 "Not_Active" 1 "Low_Pressure" 2 "High_Pressure" 3 "Invalid" ;
VAL_ 758 FrntRiTyrePVal 255 "Invalid" ;
VAL_ 758 FrntRiTyrePWarn 0 "Not_Active" 1 "Low_Pressure" 2 "High_Pressure" 3 "Invalid" ;
VAL_ 758 ReLeTyrePVal 255 "Invalid" ;
VAL_ 758 ReLeTyrePWarn 0 "Not_Active" 1 "Low_Pressure" 2 "High_Pressure" 3 "Invalid" ;
VAL_ 758 ReRiTyrePVal 255 "Invalid" ;
VAL_ 758 ReRiTyrePWarn 0 "Not_Active" 1 "Low_Pressure" 2 "High_Pressure" 3 "Invalid" ;
VAL_ 581 BMDMAcvDcnMosSt 0 "default" 1 "power_off" 2 "unable_to_perform_power_off" 3 "reserved" ;
VAL_ 355 AVPHPPCtrlAvlStsBkp 0 "Normal" 1 "Degraded" 2 "LossOfRedundancy" 3 "Reserved" ;
VAL_ 355 AVPHPPCtrStsBkp 0 "Prim" 1 "Sec" ;
VAL_ 355 AVPHPPReqFbStsBkp 0 "Initial" 1 "Ready" 2 "Active" 3 "Fault" 4 "Notused" 5 "Notused" 6 "Notused" 7 "Notused" ;
VAL_ 355 AVPHPPReqFltStsBkp 0 "Normal" 1 "VehicleSpeedOutOfRange" 2 "SteeringWheelTorqueOutOfRange" 3 "ImproperHandshaking" 4 "HandshakeTimeout" 5 "EPSInternalFault" 6 "Reserved" 7 "Reserved" 8 "Reserved" 9 "Reserved" 10 "Reserved" 11 "Reserved" 12 "Reserved" 13 "Reserved" 14 "Reserved" 15 "Reserved" ;
VAL_ 355 FailrStsBkp 0 "SteerNormal" 1 "SteerAssitTempRed" 2 "SteerAssitServReq" 3 "SteerAssitErrStopVehicle" 4 "Notused" 5 "Notused" 6 "Notused" 7 "Notused" ;
VAL_ 994 CcwEOTDetBkp 0 "Not_Learned" 1 "Learned" ;
VAL_ 994 CwEOTDetBkp 0 "Not_Learned" 1 "Learned" ;
VAL_ 200 PinionSteerAglSpdVldBkp 0 "Valid" 1 "Invalid" ;
VAL_ 200 PinionSteerAglSpdVldBkpV2C 0 "Valid" 1 "Invalid" ;
VAL_ 200 PinionSteerAglVldBkp 0 "Valid" 1 "Invalid" ;
VAL_ 200 PinionSteerAglVldBkpV2C 0 "Valid" 1 "Invalid" ;
VAL_ 200 SteerWhlTqVldBkp 0 "Valid" 1 "Invalid" ;
VAL_ 515 VCUExtmPfmncMod 0 "Not_active" 1 "Active" ;
VAL_ 515 VCUTrlrModStSts 0 "not_active" 1 "active" ;
VAL_ 515 VCUWashModStSts 0 "not_active" 1 "active" ;
VAL_ 656 AmbTEstimdVld 0 "Not_Valid" 1 "Valid" ;
VAL_ 656 EdsCircCooltTVld 0 "Not_Valid" 1 "Valid" ;
VAL_ 656 LRR2LoPwrSplySts 0 "Off" 1 "On" ;
VAL_ 656 LRRLoPwrSplySts 0 "Off" 1 "On" ;
VAL_ 656 VCUBattOverHeatWarn 0 "not_active" 1 "active" ;
VAL_ 656 VCUDrvMotFltWarn 0 "not_active" 1 "active" ;
VAL_ 656 VCUDrvMotOverHeatWarn 0 "Not_active" 1 "Active" ;
VAL_ 656 VCUDrvSysLimdWarn 0 "not_active" 1 "active" ;
VAL_ 656 VCUEstimdCrsRng 2047 "Invalid" ;
VAL_ 656 VCUEstimdCrsRngVld 0 "invalid" 1 "valid" ;
VAL_ 656 VCUGearChgFailInde 0 "No_request" 1 "Please_brake" 2 "Vehicle_speed_high" 3 "Charging_plug_insertion" 4 "EPB_failure" 5 "E_motor_failure" 6 "Connect_the_key_and_press_SSB" 7 "Press_SSB" 8 "Show_Room_Keep_Park" 9 "LV_System_Failure" 10 "HV_System_Failure" 11 "Immobilizer_Not_Pass" 12 "Trailer_Mode_Not_Shift" 13 "Shifter_Failure" ;
VAL_ 656 VCUHvBattSysFltIndcr 0 "not_active" 1 "active" ;
VAL_ 656 VCUHvBattSysFltWarn 0 "not_active" 1 "active" ;
VAL_ 656 VCUHvPwrSysCutOff 0 "not_active" 1 "active" ;
VAL_ 656 VCUHVSysFltWarnSts 0 "no_warning" 1 "reserved" 2 "HV_System_Fault_warning_Level2" 3 "reserved" 4 "HV_System_Fault_warning_Level4" 5 "HV_System_Fault_warning_Level5" 6 "HV_System_Fault_warning_Level6" 7 "reserved" 8 "HV_System_Fault_warning_Level8" 9 "HV_System_Fault_warning_Level9" 10 "reserved" 11 "reserved" 12 "reserved" 13 "reserved" 14 "reserved" 15 "reserved" ;
VAL_ 656 VCUInsEgyCnsFlg 0 "Park_status" 1 "driving_status" ;
VAL_ 656 VCULoSocWarngMsg 0 "Not_active" 1 "Level1_warning" 2 "Level2_warning" ;
VAL_ 656 VCUPrpsnPwrDrt 0 "not_active" 1 "active" ;
VAL_ 656 VCUThermRunawayErrAlrm 0 "not_active" 1 "active" ;
VAL_ 656 VCUVehSysFltWarn 0 "not_active" 1 "active" ;
VAL_ 188 SuspRoadConditionForADD 0 "NA" 1 "减速带" 2 "大起伏路" 3 "小起伏路" 4 "上坡" 5 "下坡" 6 "平整路面" 7 "小粗糙路" 8 "中等粗糙路" 9 "大粗糙路" 16 "越野路" ;
VAL_ 188 VCUFrntDesTqWoIntvVld 0 "Invalid" 1 "Valid" ;
VAL_ 188 VCUFrntMotActSpdVld 0 "Invalid" 1 "Valid" ;
VAL_ 188 VCUFrntMotActTqVld 0 "Invalid" 1 "Valid" ;
VAL_ 188 VCUFrntMotWhlTqReqVld 0 "Invalid" 1 "Valid" ;
VAL_ 188 VCUFrntWhlTqMaxAvlVld 0 "Invalid" 1 "Valid" ;
VAL_ 188 VCUFrntWhlTqMinAvlVld 0 "Invalid" 1 "Valid" ;
VAL_ 188 VCUReDesTqWoIntvVld 0 "Invalid" 1 "Valid" ;
VAL_ 188 VCUReMotActSpdVld 0 "Invalid" 1 "Valid" ;
VAL_ 188 VCUReMotActTqVld 0 "Invalid" 1 "Valid" ;
VAL_ 188 VCUReMotWhlTqReqVld 0 "Invalid" 1 "Valid" ;
VAL_ 188 VCUReWhlTqMaxAvlVld 0 "Invalid" 1 "Valid" ;
VAL_ 188 VCUReWhlTqMinAvlVld 0 "Invalid" 1 "Valid" ;
VAL_ 188 VCUWhlTqMaxAvlVld 0 "Not_validate;" 1 "Valiate;" ;
VAL_ 188 VehLatSpdEstdVld 0 "NotValid" 1 "Valid" ;
VAL_ 188 VehLgtSpdEstdVld 0 "NotValid" 1 "Valid" ;
VAL_ 607 AswmLinComFltSts 0 "No_Fault" 1 "Node_Miss" ;
VAL_ 607 HandOnDetnStsSigGrpLinErr 0 "NoErr" 1 "CounterErr" 2 "CRCErr" 3 "CounterErr_CRCErr" ;
VAL_ 607 HandsOnDetectionErrorStatus 0 "NoError" 1 "Error" ;
VAL_ 607 HandsOnDetectionStatus 0 "No_Detect" 1 "Detect" ;
VAL_ 607 StsOfBSDLampLe 0 "Off" 1 "On" 2 "Err" 3 "Resd" ;
VAL_ 892 DrvrOcupcySts 0 "Empty" 1 "Occupied" 2 "Invaild_STG" 3 "Invaild_STB_OL" ;
VAL_ 616 RlsAutWinWipgSpdCmd 0 "Switch_wiper_off" 1 "40_times_per_minute" 2 "45_times_per_minute" 3 "48_times_per_minute" 4 "51_times_per_minute" 5 "54_times_per_minute" 6 "57_times_per_minute" 7 "60_times_per_minute" ;
VAL_ 616 RlsFwdLiSnsrVal 32767 "Invalid" ;
VAL_ 616 RlsFwdLiSnsrValUnit 0 "1lux" 1 "10lux" 2 "100lux" 3 "1000lux" ;
VAL_ 616 RlsHudSnsrVal 32767 "Invalid" ;
VAL_ 616 RlsHudSnsrValUnit 0 "1lux" 1 "10lux" 2 "100lux" 3 "1000lux" ;
VAL_ 616 RlsLiSigGrpLinErr 0 "NoErr" 1 "CounterErr" 2 "CRCErr" 3 "CounterErr_CRCErr" ;
VAL_ 616 RlsLiSnsrFwdFlt 0 "No_Fault" 1 "Fault" ;
VAL_ 616 RlsLiSnsrIRFlt 0 "No_Fault" 1 "Fault" ;
VAL_ 616 RlsLiSnsrTopFlt 0 "No_Fault" 1 "Fault" ;
VAL_ 616 RlsLiSwtReq 0 "Switch_ligt_off" 1 "Switch_ligt_on" 2 "Reserved" 3 "Invalid" ;
VAL_ 616 RlsOutdBriSts 0 "Day" 1 "Night" 2 "Tunnel" 3 "Darkstart" 4 "Invalid" ;
VAL_ 616 RlsSts 0 "Rls_normal" 1 "Rls_Low_voltage" 2 "Rls_Over_voltage" 3 "Rls_Over_Temperature" 4 "Rls_communication_error" 5 "Rls_Hardware_fault" 6 "Not_determined" 7 "Invld" ;
VAL_ 616 RlsTopLiSnsrVal 32767 "Invalid" ;
VAL_ 616 RlsTopLiSnsrValUnit 0 "1lux" 1 "10lux" 2 "100lux" 3 "1000lux" ;
VAL_ 616 StsOfBSDLampRi 0 "Off" 1 "On" 2 "Err" 3 "Resd" ;
VAL_ 893 PassOcupcySts 0 "Empty" 1 "Occupied" 2 "Invaild_STG" 3 "Invaild_STB_OL" ;
VAL_ 342 ASCFltSts 0 "No_Fault" 1 "Level_control_restriction" 2 "Level_control_not_available" 3 "Level_control_not_available_caused_by_system_over_heated" ;
VAL_ 342 CDCFltSts 0 "No_Fault" 1 "Damper_control_restriction" 2 "Damper_control_not_available" 3 "Damper_control_not_available_caused_by_system_over_heated" ;
VAL_ 342 CurDampgCtrlMod 0 "Comfort" 1 "Normal" 2 "Sport" 3 "Battle" ;
VAL_ 342 ESPEnaReq 0 "No_Request" 1 "Request" ;
VAL_ 342 JackModSts 0 "Jack_Mode_OFF" 1 "Jack_Mode_ON" ;
VAL_ 342 LvlAdjmtSts 0 "No_action" 1 "Lowering" 2 "Lifting" 3 "Pending" 4 "Rear_lowering" 5 "Rear_lifting" 6 "Rear_pending" ;
VAL_ 342 LvlModAct 0 "EasyLoad" 1 "HL2" 2 "HL1" 3 "NL" 4 "LL1" 5 "LL2" ;
VAL_ 342 SCUExtmHeiSts 0 "Normal" 1 "Extreme_High" 2 "Extreme_Low" ;
VAL_ 342 SCULimSpdTqReq 0 "No_request" 1 "Request" ;
VAL_ 342 SCUWarnLampReq 0 "No_Request" 1 "Yellow_warning_light" 2 "Red_warning_light" ;
VAL_ 342 SCUWarnMsgASC 0 "NoRequest" 1 "SCU_ASC_SysFlt_OverHigh_空气悬架系统故障，车辆过高，请低速慢行" 2 "SCU_ASC_SysFlt_OverLow_空气悬架系统故障，车辆过低，离地间隙受限" 3 "SCU_ASC_SysFlt_空气悬架系统故障，请检修" 4 "Reserved0" 5 "SCU_ASC_Overheatd_空气悬架系统过热，请等待系统冷却" 6 "SCU_ASC_SystemFilling_空气悬架系统正在充气" 7 "Reserved" ;
VAL_ 342 SCUWarnMsgCDC 0 "NoRequest" 1 "SCU_CDC_SysFlt_电控减振系统故障，请检修" 2 "SCU_CDC_FcnLim_电控减振系统性能下降" 3 "Reserved" ;
VAL_ 345 DiagcExtActv 0 "No" 1 "Yes" ;
VAL_ 549 ADSELKSwtSet 0 "No_Command" 1 "Off" 2 "Middle" 3 "High" ;
VAL_ 549 ADSFltQuitReqFrmDCD 0 "default" 1 "Quit_Request" 2 "reserved_1" 3 "reserved_2" ;
VAL_ 549 DCDAvmFrCamSts 0 "OFF" 1 "Standby" 2 "Normal" 3 "Blocked(Reserved)" 4 "Error" 5 "Reserved1" 6 "Reserved2" 7 "Reserved3" ;
VAL_ 549 DCDAvmLeCamSts 0 "OFF" 1 "Standby" 2 "Normal" 3 "Blocked(Reserved)" 4 "Error" 5 "Reserved1" 6 "Reserved2" 7 "Reserved3" ;
VAL_ 549 DCDAvmReCamSts 0 "OFF" 1 "Standby" 2 "Normal" 3 "Blocked(Reserved)" 4 "Error" 5 "Reserved1" 6 "Reserved2" 7 "Reserved3" ;
VAL_ 549 DCDAvmRiCamSts 0 "OFF" 1 "Standby" 2 "Normal" 3 "Blocked(Reserved)" 4 "Error" 5 "Reserved1" 6 "Reserved2" 7 "Reserved3" ;
VAL_ 549 DCDDisplayFailSts 0 "No_Failure" 1 "No_Comm_with_CIDM" 2 "CIDM_internal_display_error" 3 "DCD_actively_shutdown_display" 4 "CIDM_freeze_frame_detected" 5 "reserved_1" 6 "reserved_2" 7 "reserved_3" ;
VAL_ 1023 VidBlkId 0 "Invalid" 1 "Block_1" 2 "Block_2" 3 "Block_3" ;
VAL_ 1023 VinVINBlkID 0 "Invalid" 1 "Block_1" 2 "Block_2" 3 "Block_3" ;
VAL_ 389 AdasSwt 0 "Not_Pressed" 1 "Pressed" 2 "Error" 3 "Reserved" ;
VAL_ 389 AdasSwtSigGrpLinErr 0 "NoErr" 1 "CounterErr" 2 "CRCErr" 3 "CounterErr_CRCErr" ;
VAL_ 389 HoodOpenClsSts 0 "Ukwn" 1 "Open" 2 "Clsd" ;
VAL_ 389 LeKnobCounter 255 "Invalid" ;
VAL_ 389 LeMFctActSgCe 0 "Not_Pressed" 1 "Pressed" 2 "Error" 3 "Reserved" ;
VAL_ 389 LeMFctActSgLe 0 "Not_Pressed" 1 "Pressed" 2 "Error" 3 "Reserved" ;
VAL_ 389 LeMFctActSgRi 0 "Not_Pressed" 1 "Pressed" 2 "Error" 3 "Reserved" ;
VAL_ 389 RiMFctActSgCe 0 "Not_Pressed" 1 "Pressed" 2 "Error" 3 "Reserved" ;
VAL_ 389 TrOpenClsSts 0 "Ukwn" 1 "Open" 2 "Clsd" ;
VAL_ 520 ARSPosnSts 0 "Unknown" 1 "P0" 2 "P1" 3 "P2" 4 "P3" 5 "OpenHardStop" 6 "CloseHardStop" 7 "LessPo" 8 "MoreP3" 9 "OtherPosn" 10 "BtwP0P1" 11 "BtwP1P2" 12 "BtwP2P3" ;
VAL_ 520 RlsLinComFltSts 0 "No_Fault" 1 "Node_Miss" ;
VAL_ 768 FLRLLoPwrSplySts 0 "Off" 1 "On" ;
VAL_ 768 FrntShdADCameraDefrstErrFb 0 "Flt_NoFault" 1 "Flt_Fault" ;
VAL_ 768 FrntShdADCameraDefrstSts 0 "Off" 1 "On" ;
VAL_ 768 IMULoPwrSplySts 0 "Off" 1 "On" ;
VAL_ 768 LockgCenLockSts 0 "Not_defined" 1 "Unlocked" 2 "Locked" 3 "Partially_unlocked" ;
VAL_ 768 RSRLoPwrSplySts 0 "Off" 1 "On" ;
VAL_ 1313 VCCDChassisBkpActiveWakeup 0 "passive_wakeup" 1 "active_Wakeup" ;
VAL_ 1313 VCCDChassisBkpRepeatMsgReq 0 "not_requested" 1 "requested" ;
VAL_ 1313 VCCDChassisBkpRepeatMsgSt 0 "Not_in_Repeat_Message_State" 1 "In_Repeat_Message_State" ;
SIG_GROUP_ 688 ParkSwtStsSigGrp 1 : APASwtStsFrmADD APASwtUnavlRsnFrmADD AVPSwtStsFrmADD AVPSwtUnavlRsnFrmADD HPPBckGrLearFrmADD HPPBckGrLearUnavlRsnFrmADD HPPSwtStsFrmADD HPPSwtUnavlRsnFrmADD ParkSwtStsSigGrpChks ParkSwtStsSigGrpCntr;
SIG_GROUP_ 693 ParkTarPosnSigGrp 1 : ParkOutTarDirFrmADD ParkSlotTarFrmADD ParkTarPosnSigGrpChks ParkTarPosnSigGrpCntr;
SIG_GROUP_ 693 PASDistanceLevSigGrp 1 : PASDistanceLevSigGrpChks PASDistanceLevSigGrpCntr PASFLDistanceLevFrmADD PASFMLDistanceLevFrmADD PASFMRDistanceLevFrmADD PASFRDistanceLevFrmADD PASFSLDistanceLevFrmADD PASFSRDistanceLevFrmADD PASRLDistanceLevFrmADD PASRMLDistanceLevFrmADD PASRMRDistanceLevFrmADD PASRRDistanceLevFrmADD PASRSLDistanceLevFrmADD PASRSRDistanceLevFrmADD PASSDWFLSideDistanceLevFrmADD PASSDWFMLSideDistanceLevFrmADD PASSDWFMRSideDistanceLevFrmADD PASSDWFRSideDistanceLevFrmADD PASSDWRLSideDistanceLevFrmADD PASSDWRMLSideDistanceLevFrmADD PASSDWRMRSideDistanceLevFrmADD PASSDWRRSideDistanceLevFrmADD;
SIG_GROUP_ 693 PASDistanceSystemGrp 1 : PASDistanceSystemGrpChks PASDistanceSystemGrpCntr PASFLDistanceFrmADD PASFMLDistanceFrmADD PASFMRDistanceFrmADD PASFRDistanceFrmADD PASFSLDistanceFrmADD PASFSRDistanceFrmADD PASRLDistanceFrmADD PASRMLDistanceFrmADD PASRMRDistanceFrmADD PASRRDistanceFrmADD PASRSLDistanceFrmADD PASRSRDistanceFrmADD PASSDWFLSideDistanceFrmADD PASSDWFMLSideDistanceFrmADD PASSDWFMRSideDistanceFrmADD PASSDWFRSideDistanceFrmADD PASSDWRLSideDistanceFrmADD PASSDWRMLSideDistanceFrmADD PASSDWRMRSideDistanceFrmADD PASSDWRRSideDistanceFrmADD;
SIG_GROUP_ 693 PASFLBuzzerSigGrp 1 : PASBuzzerWarnMuteReqFrmADD PASFCBuzzerWarnFrmADD PASFLBuzzerSigGrpChks PASFLBuzzerSigGrpCntr PASFLBuzzerWarnFrmADD PASFRBuzzerWarnFrmADD PASRLBuzzerWarnFrmADD PASRRBuzzerWarnFrmADD;
SIG_GROUP_ 775 PASProgressSigGrp 1 : ParkProgressSigLFPosXFrmADD ParkProgressSigLFPosYFrmADD ParkProgressSigLRPosXFrmADD ParkProgressSigLRPosYFrmADD ParkProgressSigRFPosXFrmADD ParkProgressSigRFPosYFrmADD ParkProgressSigRRPosXFrmADD ParkProgressSigRRPosYFrmADD PASProgressSigGrpChks PASProgressSigGrpCntr;
SIG_GROUP_ 775 PASWorkingModeSigGrp 1 : PASSubFunAvaiFrmADD PASWorkingModeFrmADD PASWorkingModeSigGrpChks PASWorkingModeSigGrpCntr;
SIG_GROUP_ 239 ADDIMUSigGrp 1 : ADDIMUSigGrpChks ADDIMUSigGrpCntr XAccelStaFrmADD XAccelValFrmADD XAngRateStaFrmADD XAngRateValFrmADD YAccelStaFrmADD YAccelValFrmADD YAngRateStaFrmADD YAngRateValFrmADD ZAccelStaFrmADD ZAccelValFrmADD ZAngRateStaFrmADD ZAngRateValFrmADD;
SIG_GROUP_ 487 BcpBrkSysIndcnBkpSigGrp 1 : BcpBrkSysIndcnBkpSigGrpChks BcpBrkSysIndcnBkpSigGrpCntr BrkSysBrkPedlAppld BrkSysBrkPedlAppldVld BrkSysEnaActvCtrlByDrvr BrkSysFTarDrvr BrkSysFTarDrvrVld BrkSysPRednPotnl BrkSysPRednPotnlVld BrkSysWarnLampReq;
SIG_GROUP_ 657 BLEM2VCCDForLocn1 1 : BLEM2VCCDForLocn10 BLEM2VCCDForLocn11 BLEM2VCCDForLocn12 BLEM2VCCDForLocn13 BLEM2VCCDForLocn14 BLEM2VCCDForLocn15 BLEM2VCCDForLocn16 BLEM2VCCDForLocn17 BLEM2VCCDForLocn18 BLEM2VCCDForLocn19 BLEM2VCCDForLocn1A BLEM2VCCDForLocn1B BLEM2VCCDForLocn1C BLEM2VCCDForLocn1D BLEM2VCCDForLocn1F;
SIG_GROUP_ 665 BLEM2VCCDForLocn2 1 : BLEM2VCCDForLocn20 BLEM2VCCDForLocn21 BLEM2VCCDForLocn22 BLEM2VCCDForLocn23 BLEM2VCCDForLocn24 BLEM2VCCDForLocn25 BLEM2VCCDForLocn26 BLEM2VCCDForLocn27 BLEM2VCCDForLocn28 BLEM2VCCDForLocn29 BLEM2VCCDForLocn2A BLEM2VCCDForLocn2B BLEM2VCCDForLocn2C BLEM2VCCDForLocn2D BLEM2VCCDForLocn2F;
SIG_GROUP_ 817 BLEM2VCCDForLocn4 1 : BLEM2VCCDForLocn40 BLEM2VCCDForLocn41 BLEM2VCCDForLocn42 BLEM2VCCDForLocn43 BLEM2VCCDForLocn44 BLEM2VCCDForLocn45 BLEM2VCCDForLocn46 BLEM2VCCDForLocn47 BLEM2VCCDForLocn48 BLEM2VCCDForLocn49 BLEM2VCCDForLocn4A BLEM2VCCDForLocn4B BLEM2VCCDForLocn4C BLEM2VCCDForLocn4D BLEM2VCCDForLocn4F;
SIG_GROUP_ 826 BLEM2VCCDForLocn3 1 : BLEM2VCCDForLocn30 BLEM2VCCDForLocn31 BLEM2VCCDForLocn32 BLEM2VCCDForLocn33 BLEM2VCCDForLocn34 BLEM2VCCDForLocn35 BLEM2VCCDForLocn36 BLEM2VCCDForLocn37 BLEM2VCCDForLocn38 BLEM2VCCDForLocn39 BLEM2VCCDForLocn3A BLEM2VCCDForLocn3B BLEM2VCCDForLocn3C BLEM2VCCDForLocn3D BLEM2VCCDForLocn3F;
SIG_GROUP_ 827 BLEM2VCCDForRkeReq 1 : BLEM2VCCDForRkeReq00 BLEM2VCCDForRkeReq01 BLEM2VCCDForRkeReq02 BLEM2VCCDForRkeReq03 BLEM2VCCDForRkeReq04 BLEM2VCCDForRkeReq05 BLEM2VCCDForRkeReq06 BLEM2VCCDForRkeReq07 BLEM2VCCDForRkeReq08 BLEM2VCCDForRkeReq09 BLEM2VCCDForRkeReq10 BLEM2VCCDForRkeReq11 BLEM2VCCDForRkeReq12 BLEM2VCCDForRkeReq13 BLEM2VCCDForRkeReq14;
SIG_GROUP_ 581 BattSohSigGrp 1 : BattSoh BattSohSigGrpChks BattSohSigGrpCntr;
SIG_GROUP_ 355 EPSAVPHPPCtrlStsBkpSigGrp 1 : AVPHPPCtrlAvlStsBkp AVPHPPCtrStsBkp AVPHPPReqFbStsBkp AVPHPPReqFltStsBkp EPSAVPHPPCtrlStsBkpSigGrpChks EPSAVPHPPCtrlStsBkpSigGrpCntr;
SIG_GROUP_ 355 FailrStsBkpSigGrp 1 : FailrStsBkp FailrStsBkpSigGrpChks FailrStsBkpSigGrpCntr;
SIG_GROUP_ 200 SteeringWhlSignalBkpSigGrp 1 : PinionAglSpdBkpV2C PinionSteerAglBkp PinionSteerAglBkpV2C PinionSteerAglSpdBkp PinionSteerAglSpdVldBkp PinionSteerAglSpdVldBkpV2C PinionSteerAglVldBkp PinionSteerAglVldBkpV2C SteeringWhlSignalBkpSigGrpChks SteeringWhlSignalBkpSigGrpCntr SteerWhlTqBkp SteerWhlTqVldBkp;
SIG_GROUP_ 515 ModStsSigGrp 1 : VCUTrlrModStSts;
SIG_GROUP_ 656 InsEgyCnsSigGrp 1 : InsEgyCnsSigGrpChks InsEgyCnsSigGrpCntr VCUEgyCnsInCurDrvCyc VCUEstimdCrsRng VCUEstimdCrsRngForCltc VCUEstimdCrsRngVld VCUInsEgyCnsDurgDrvg VCUInsEgyCnsDurgStsl VCUInsEgyCnsFlg;
SIG_GROUP_ 656 VehSysFltWarnSigGrp 1 : VCUBattOverHeatWarn VCUDrvMotFltWarn VCUDrvMotOverHeatWarn VCUDrvSysLimdWarn VCUGearChgFailInde VCUHvBattSysFltIndcr VCUHvBattSysFltWarn VCUHvPwrSysCutOff VCUHVSysFltWarnSts VCULoSocWarngMsg VCUPrpsnPwrDrt VCUThermRunawayErrAlrm VCUVehSysFltWarn VehSysFltWarnSigGrpChks VehSysFltWarnSigGrpCntr;
SIG_GROUP_ 188 FrntMotCtrlSigGrp 1 : FrntMotCtrlSigGrpChks FrntMotCtrlSigGrpCntr VCUFrntDesTqWoIntv VCUFrntDesTqWoIntvVld VCUFrntMotActSpd VCUFrntMotActSpdVld VCUFrntMotActTq VCUFrntMotActTqVld VCUFrntMotWhlTqReq VCUFrntMotWhlTqReqVld VCUFrntWhlTqMaxAvl VCUFrntWhlTqMaxAvlVld VCUFrntWhlTqMinAvl VCUFrntWhlTqMinAvlVld;
SIG_GROUP_ 188 ReMotCtrlSigGrp 1 : ReMotCtrlSigGrpChks ReMotCtrlSigGrpCntr VCUReDesTqWoIntv VCUReDesTqWoIntvVld VCUReMotActSpd VCUReMotActSpdVld VCUReMotActTq VCUReMotActTqVld VCUReMotWhlTqReq VCUReMotWhlTqReqVld VCUReWhlTqMaxAvl VCUReWhlTqMaxAvlVld VCUReWhlTqMinAvl VCUReWhlTqMinAvlVld VCUWhlTqMaxAvl VCUWhlTqMaxAvlVld;
SIG_GROUP_ 188 VDMVehSpdEstmGrp 1 : VDMLgtWhlSpdFL VDMLgtWhlSpdFR VDMLgtWhlSpdRL VDMLgtWhlSpdRR VDMVehSpdEstmGrpChks VDMVehSpdEstmGrpCntr VehBodySideSlipAng VehLatSpdEstd VehLatSpdEstdVld VehLgtSpdEstd VehLgtSpdEstdVld;
SIG_GROUP_ 607 HandOnDetnStsSigGrp 1 : HandOnDetnStsSigGrpChks HandOnDetnStsSigGrpCntr HandOnDetnStsSigGrpLinErr HandsOnDetectionErrorStatus HandsOnDetectionStatus;
SIG_GROUP_ 892 DrvrOcupcyStsGroup 1 : DrvrOcupcySts DrvrOcupcyStsGroupChks DrvrOcupcyStsGroupCntr;
SIG_GROUP_ 616 RlsAutWinWipgSpdCmdSigGrp 1 : RlsAutWinWipgSpdCmd RlsAutWinWipgSpdCmdSigGrpChks RlsAutWinWipgSpdCmdSigGrpCntr;
SIG_GROUP_ 616 RlsLiSig1Grp 1 : RlsFwdLiSnsrVal RlsFwdLiSnsrValUnit RlsHudSnsrVal RlsHudSnsrValUnit RlsIRVal RlsLiSig1GrpChks RlsLiSig1GrpCntr RlsLiSnsrFwdFlt RlsLiSnsrIRFlt RlsLiSnsrTopFlt;
SIG_GROUP_ 616 RlsLiSig2Grp 1 : RlsLiSig2GrpChks RlsLiSig2GrpCntr RlsLiSigGrpLinErr RlsLiSwtReq RlsOutdBriSts RlsSts RlsTopLiSnsrVal RlsTopLiSnsrValUnit;
SIG_GROUP_ 342 SCUWarnSigGrp 1 : ASCFltSts CDCFltSts ESPEnaReq SCUExtmHeiSts SCULimSpdTqReq SCUWarnLampReq SCUWarnMsgASC SCUWarnMsgCDC SCUWarnSigGrpChks SCUWarnSigGrpCntr;
SIG_GROUP_ 549 DCDAvmCamE2ESigGrp 1 : DCDAvmCamE2ESigGrpChks DCDAvmCamE2ESigGrpCntr DCDAvmFrCamSts DCDAvmLeCamSts DCDAvmReCamSts DCDAvmRiCamSts;
SIG_GROUP_ 1023 Vid 1 : VidBlkId VidSignalPos1 VidSignalPos2 VidSignalPos3 VidSignalPos4 VidSignalPos5 VidSignalPos6 VidSignalPos7;
SIG_GROUP_ 135 VehCfgPrm 1 : VehCfgPrmBlkIDBytePosn1 VehCfgPrmCCPBytePosn2 VehCfgPrmCCPBytePosn3 VehCfgPrmCCPBytePosn4 VehCfgPrmCCPBytePosn5 VehCfgPrmCCPBytePosn6 VehCfgPrmCCPBytePosn7 VehCfgPrmCCPBytePosn8;
SIG_GROUP_ 389 AdasSwtSigGrp 1 : AdasSwt AdasSwtSigGrpChks AdasSwtSigGrpCntr AdasSwtSigGrpLinErr;
